VERSION " "
NS_ :

BS_:

BU_: ACU BDCM EPS BMS MCU VCU1 CDU TBOX EHB ESC Tester IHU PLG PTC EACP CLM ICU TAP ALM
BO_ 1077 MCU_Fr06_435: 8 MCU
 SG_ MCU6IGBTDrvChipAbnor : 53|1@0+ (1,0) [0|1] ""  TBOX
 SG_ MCU6VCUTimeout : 52|1@0+ (1,0) [0|1] ""  TBOX
 SG_ MCU6VCUDlcErr : 51|1@0+ (1,0) [0|1] ""  TBOX
 SG_ MCU6CanBusOff : 50|1@0+ (1,0) [0|1] ""  TBOX
 SG_ MCU6BMSTimeoutFault : 49|1@0+ (1,0) [0|1] ""  TBOX
 SG_ MCU6BMSTimeout : 48|1@0+ (1,0) [0|1] ""  TBOX
 SG_ MCU6BMSDlcErr : 47|1@0+ (1,0) [0|1] ""  TBOX
 SG_ MCU6SPIFPGA2CPLD : 46|1@0+ (1,0) [0|1] ""  TBOX
 SG_ MCU6DrvPwrAbnor : 45|1@0+ (1,0) [0|1] ""  TBOX
 SG_ MCU6Redundant12V : 44|1@0+ (1,0) [0|1] ""  TBOX
 SG_ MCU6HwFault_@2WG7274 : 43|1@0+ (1,0) [0|1] ""  TBOX
 SG_ MCU6HwWarn : 42|1@0+ (1,0) [0|1] ""  TBOX
 SG_ MCU6NTCRagChgErr : 41|1@0+ (1,0) [0|1] ""  TBOX
 SG_ MCU6ModReqErr : 40|1@0+ (1,0) [0|1] ""  TBOX
 SG_ MCU6WhlSpdDiffOv : 39|1@0+ (1,0) [0|1] ""  TBOX
 SG_ MCU6HvErr_@2WG7270 : 38|1@0+ (1,0) [0|1] ""  TBOX
 SG_ MCU6HvRddOv : 37|1@0+ (1,0) [0|1] ""  TBOX
 SG_ MCU6HvRddChkErr : 36|1@0+ (1,0) [0|1] ""  TBOX
 SG_ MCU6TempChkErr : 35|1@0+ (1,0) [0|1] ""  TBOX
 SG_ MCU6PosSensErr : 34|1@0+ (1,0) [0|1] ""  TBOX
 SG_ MCU6PhaCurUnrea : 33|1@0+ (1,0) [0|1] ""  TBOX
 SG_ MCU6FocCtrlErr_@2WG726F : 32|1@0+ (1,0) [0|1] ""  TBOX
 SG_ MCU6BatOffErr : 31|1@0+ (1,0) [0|1] ""  TBOX
 SG_ MCU6FwCurErr : 30|1@0+ (1,0) [0|1] ""  TBOX
 SG_ MCU6AscOrFwErr_@2WG726E : 29|1@0+ (1,0) [0|1] ""  TBOX
 SG_ MCU6flgDisChgFail : 28|1@0+ (1,0) [0|1] ""  TBOX
 SG_ MCU6TrqChkError_@2WG7268 : 27|1@0+ (1,0) [0|1] ""  TBOX
 SG_ MCU6EmacBlkd : 26|1@0+ (1,0) [0|1] ""  TBOX
 SG_ MCU6IphaErr : 25|1@0+ (1,0) [0|1] ""  TBOX
 SG_ MCU6OcLimErr : 24|1@0+ (1,0) [0|1] ""  TBOX
 SG_ MCU6InPwrFault_@2WG726D : 23|1@0+ (1,0) [0|1] ""  TBOX
 SG_ MCU6InPwrSevDer : 22|1@0+ (1,0) [0|1] ""  TBOX
 SG_ MCU6InPwrMilDer : 21|1@0+ (1,0) [0|1] ""  TBOX
 SG_ MCU6InPwrWarn : 20|1@0+ (1,0) [0|1] ""  TBOX
 SG_ MCU6SpdHiWA : 19|1@0+ (1,0) [0|1] ""  TBOX
 SG_ MCU6SpdOv : 18|1@0+ (1,0) [0|1] ""  TBOX
 SG_ MCU6PosSpeSigAmpRngErr : 17|1@0+ (1,0) [0|1] ""  TBOX
 SG_ MCU6PosSpeSigAmpRngDer : 16|1@0+ (1,0) [0|1] ""  TBOX
 SG_ MCU6PosSpeSigSinCosSqrErr_@2WG726C : 15|1@0+ (1,0) [0|1] ""  TBOX
 SG_ MCU6PhaCurOc_@2WG7273 : 14|1@0+ (1,0) [0|1] ""  TBOX
 SG_ MCU6PhaCurShr : 13|1@0+ (1,0) [0|1] ""  TBOX
 SG_ MCU6UKl30OvHiRng : 12|1@0+ (1,0) [0|1] ""  TBOX
 SG_ MCU6UKl30Ov : 11|1@0+ (1,0) [0|1] ""  TBOX
 SG_ MCU6UKl30OvLo : 10|1@0+ (1,0) [0|1] ""  TBOX
 SG_ MCU6UdcHiDerAct : 9|1@0+ (1,0) [0|1] ""  TBOX
 SG_ MCU6UdcLoDerAct : 8|1@0+ (1,0) [0|1] ""  TBOX
 SG_ MCU6UdcLnkOv_@2WG726A : 7|1@0+ (1,0) [0|1] ""  TBOX
 SG_ MCU6UdcLnkUnv_@2WG7269 : 6|1@0+ (1,0) [0|1] ""  TBOX
 SG_ MCU6TempEmDerAct : 5|1@0+ (1,0) [0|1] ""  TBOX
 SG_ MCU6TSttrShr : 4|1@0+ (1,0) [0|1] ""  TBOX
 SG_ MCU6TSttrOvHiLim_@2WG7272 : 3|1@0+ (1,0) [0|1] ""  TBOX
 SG_ MCU6TempIGBTDerAct : 2|1@0+ (1,0) [0|1] ""  TBOX
 SG_ MCU6TempIGBTShr : 1|1@0+ (1,0) [0|1] ""  TBOX
 SG_ MCU6TempIGBTHiLim_@2WG7271 : 0|1@0+ (1,0) [0|1] ""  TBOX
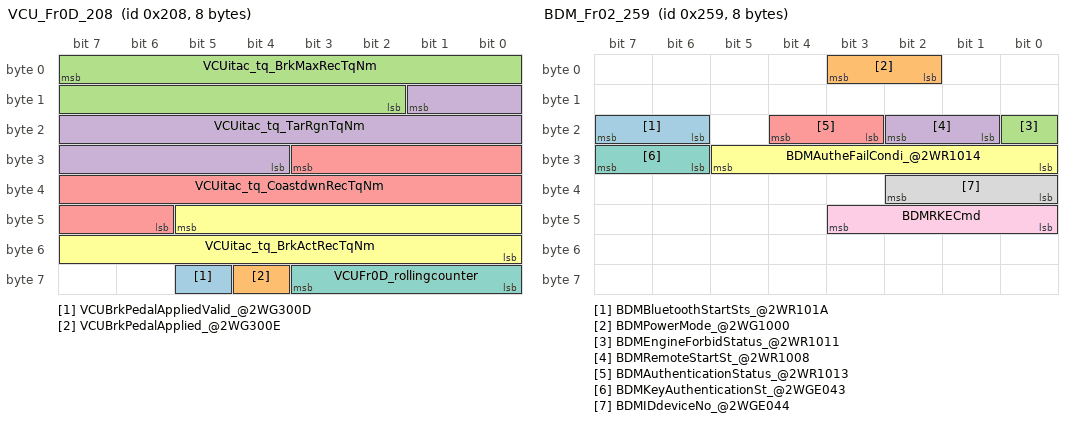
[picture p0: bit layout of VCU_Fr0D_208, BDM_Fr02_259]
BO_ 520 VCU_Fr0D_208: 8 VCU
 SG_ VCUBrkPedalAppliedValid_@2WG300D : 61|1@0+ (1,0) [0|0] ""  ESC
 SG_ VCUBrkPedalApplied_@2WG300E : 60|1@0+ (1,0) [0|0] ""  ESC
 SG_ VCUitac_tq_BrkMaxRecTqNm : 7|14@0+ (1,-16000) [-16000|0] "Nm"  ESC,EHB
 SG_ VCUitac_tq_TarRgnTqNm : 9|14@0+ (1,-16000) [-16000|0] "Nm"  ESC,EHB
 SG_ VCUitac_tq_CoastdwnRecTqNm : 27|14@0+ (1,-16000) [-16000|0] "Nm"  ESC,EHB
 SG_ VCUitac_tq_BrkActRecTqNm : 45|14@0+ (1,-16000) [-16000|0] "Nm"  ESC,EHB
 SG_ VCUFr0D_rollingcounter : 59|4@0+ (1,0) [0|15] ""  ESC,EHB
BO_ 698 APA_Fr02_2BA: 8 APA
 SG_ EXTAPAWorkStsCH_@2WG7063 : 39|3@0+ (1,0) [0|7] ""  VCU,EPS,ESC,ICU,IHU
BO_ 234 FLC_Fr01_0EA: 8 FLC
 SG_ EXTFLCStatus_@2WG7162 : 44|2@0+ (1,0) [0|3] ""  FLR
BO_ 522 FLR_Fr03_0x20A: 8 FLR
 SG_ EXTFLRAEBFailinfo_@2WG7161 : 31|2@0+ (1,0) [0|3] ""  ESC,ICU,IHU
BO_ 537 FLR_Fr02_0x219: 8 FLR
 SG_ EXTFLRACCSysFailure_@2WG7060 : 7|2@0+ (1,0) [0|3] ""  ESC,FLC,ICU
BO_ 1266 BTM_Fr01_4F2: 8 BTM
 SG_ BTM01ChargingCmd_@2WR1020 : 9|2@0+(1,0)[0|3] "" TBOX
BO_ 563 ACU_Fr01_233: 8 ACU
 SG_ ACUPsSeatBeltRSt_@2WGF045 : 7|2@0+(1,0)[0|3] "" Vector__XXX
 SG_ ACUDrvSeatBeltRSt_@2WGF044 : 5|2@0+(1,0)[0|3] "" Vector__XXX
 SG_ ACUAirBagFailSts_@2WG722D : 1|2@0+(1,0)[0|3] "" Vector__XXX
 SG_ ACUCrashOutputSts_@2WGE009 : 15|2@0+(1,0)[0|3] "" Vector__XXX
 SG_ EXTACUCrashOutputSts_@2WG7222 : 15|2@0+(1,0)[0|3] "" Vector__XXX
 SG_ ACU节点丢失_@2N001 : 15|2@0+(1,0)[0|3] "" Vector__XXX
BO_ 825 BDM_Fr01_339: 8 BDCM
 SG_ BDMAlarmMode_@2WG704C : 2|3@0+(1,0)[0|7] "" Vector__XXX
 SG_ BDMBackDoorAjar_@2WGC00E : 7|3@0+(1,0)[0|7] "" Vector__XXX
 SG_ BDMDriverDoorAjar_@2WGC00A : 9|2@0+(1,0)[0|3] "" Vector__XXX
 SG_ BDMPassDoorAjar_@2WGC00B : 11|2@0+(1,0)[0|3] "" Vector__XXX
 SG_ BDMRearDriverDoorAjar_@2WGC00C : 13|2@0+(1,0)[0|3] "" Vector__XXX
 SG_ BDMRearPassDoorAjar_@2WGC00D : 15|2@0+(1,0)[0|3] "" Vector__XXX
 SG_ BDMPositionLampSt_@2WGC003 : 16|1@0+(1,0)[0|1] "" Vector__XXX
 SG_ BDMBacklightStatus : 17|1@0+(1,0)[0|1] "" Vector__XXX
 SG_ BDMLowBeamSt_@2WGC009 : 18|1@0+(1,0)[0|1] "" Vector__XXX
 SG_ BDMLeftTurnLightSt : 19|1@0+(1,0)[0|1] "" Vector__XXX
 SG_ BDMRightTurnLightSt : 20|1@0+(1,0)[0|1] "" Vector__XXX
 SG_ BDMRearFogLampSt_@2WGC002 : 21|1@0+(1,0)[0|1] "" Vector__XXX
 SG_ BDMFrontFogLampSt : 22|1@0+(1,0)[0|1] "" Vector__XXX
 SG_ BDMDRLSt : 23|1@0+(1,0)[0|1] "" Vector__XXX
 SG_ BDMHighBeamSt_@2WGC008 : 24|1@0+(1,0)[0|1] "" Vector__XXX
 SG_ BDMHazardLampSt_@2WGF015 : 25|1@0+(1,0)[0|1] "" Vector__XXX
 SG_ BDMFrontWiperSt : 34|3@0+(1,0)[0|7] "" Vector__XXX
 SG_ BDMDoorLockSts_@2WGF000 : 38|1@0+(1,0)[0|1] "" Vector__XXX
 SG_ BDMRearDefrostSts : 39|1@0+(1,0)[0|1] "" Vector__XXX
 SG_ BDMLeftTurnLightSW_@2WGC006 : 31|2@0+ (1,0) [0|3] ""  TBOX
 SG_ BDMRightTurnLightSW_@2WGC007 : 31|2@0+ (1,0) [0|3] ""  TBOX
 SG_ BDMTrunkLockSts_@2WGF004 : 43|1@0+(1,0)[0|1] "" Vector__XXX
 SG_ BDMFindCarSts_@2WR1002 : 42|1@1+(1,0)[0|1] "" Vector__XXX
 SG_ BDCM节点丢失_@2N013 : 42|1@1+(1,0)[0|1] "" Vector__XXX
BO_ 601 BDM_Fr02_259: 8 BDCM
 SG_ BDMBluetoothStartSts_@2WR101A : 23|2@0+ (1,0) [0|0] ""  TBOX
 SG_ BDMPowerMode_@2WG1000 : 3|2@0+(1,0)[0|3] "" Vector__XXX
 SG_ BDMEngineForbidStatus_@2WR1011 : 16|1@0+(1,0)[0|1] "" Vector__XXX
 SG_ BDMRemoteStartSt_@2WR1008 : 18|2@0+(1,0)[0|3] "" Vector__XXX
 SG_ BDMAuthenticationStatus_@2WR1013 : 20|2@0+(1,0)[0|3] "" Vector__XXX
 SG_ BDMAutheFailCondi_@2WR1014 : 29|6@0+(1,0)[0|63] "" Vector__XXX
 SG_ BDMKeyAuthenticationSt_@2WGE043 : 31|2@0+(1,0)[0|3] "" Vector__XXX
 SG_ BDMIDdeviceNo_@2WGE044 : 34|3@0+(1,0)[0|7] "" Vector__XXX
 SG_ BDMRKECmd : 43|4@0+(1,0)[0|15] "" Vector__XXX
BO_ 618 BDM_Fr03_26A: 8 BDCM
 SG_ BDMDoorHandleSensorFailureInd : 1|1@0+(1,0)[0|1] "" Vector__XXX
 SG_ BDMBrakeLightSts_@2WGF01B : 2|1@0+(1,0)[0|1] "" Vector__XXX
 SG_ BDMKeyNotFindIndication : 10|1@0+(1,0)[0|1] "" Vector__XXX
 SG_ BDMKeyLowBatteryIndication : 11|1@0+(1,0)[0|1] "" Vector__XXX
 SG_ BDMKeyInIndication : 12|1@0+(1,0)[0|1] "" Vector__XXX
 SG_ BDMDepressBrakePedalIndication : 14|1@0+(1,0)[0|1] "" Vector__XXX
 SG_ BDMShiftGearToPNIndication : 15|1@0+(1,0)[0|1] "" Vector__XXX
 SG_ BDMShiftGearToPIndication : 16|1@0+(1,0)[0|1] "" Vector__XXX
 SG_ BDMBackupStartIndication : 17|1@0+(1,0)[0|1] "" Vector__XXX
 SG_ RearFogLampFailedSts : 42|1@0+(1,0)[0|1] "" Vector__XXX
 SG_ SSBFailedSts : 45|1@0+(1,0)[0|1] "" Vector__XXX
 SG_ CHMSLFailedSts : 21|1@0+(1,0)[0|1] "" Vector__XXX
 SG_ StopLampFailedSts_@2WG7149 : 22|1@0+(1,0)[0|1] "" Vector__XXX
 SG_ SRMSunroofPosition_@2WR1005 : 34|3@0+(1,0)[0|7] "" Vector__XXX
 SG_ SRMSunshadePosition : 47|2@0+(1,0)[0|3] "" Vector__XXX
 SG_ DriverHeatingStatus_@2WR100D : 50|3@0+(1,0)[0|7] "" Vector__XXX
 SG_ PassengerHeatingStatus_@2WR100E : 53|3@0+(1,0)[0|7] "" Vector__XXX
 SG_ SHMLHFailure : 57|1@0+(1,0)[0|1] "" Vector__XXX
 SG_ SHMRHFailure : 56|1@0+(1,0)[0|1] "" Vector__XXX
BO_ 906 BDM_Fr04_38A: 8 BDCM
 SG_ BDMRtyreStatus : 0|1@0+(1,0)[0|1] "" Vector__XXX
 SG_ BDMRLTyreLearntSt : 1|1@0+(1,0)[0|1] "" Vector__XXX
 SG_ BDMRLTyrePressureWarn_@2WG500F : 3|2@0+(1,0)[0|3] "" Vector__XXX
 SG_ BDMRLTyreTemperatureWarn_@2WG5011 : 4|1@0+(1,0)[0|1] "" Vector__XXX
 SG_ BDMRLTyreQucikLeak_@2WG500E : 5|1@0+(1,0)[0|1] "" Vector__XXX
 SG_ BDMRLTyreSensorFailure_@2WG500D : 6|1@0+(1,0)[0|1] "" Vector__XXX
 SG_ BDMRLTyreLowBattery_@2WG5012 : 7|1@0+(1,0)[0|1] "" Vector__XXX
 SG_ BDMRLTyrePressure_@2WGF024 : 15|8@0+(3.137,0)[0|797] "" Vector__XXX
 SG_ BDMRLTyreTemperature_@2WGF023 : 23|8@0+(1,-50)[-50|204] "" Vector__XXX
 SG_ BDMRRTyreLearntSt : 25|1@0+(1,0)[0|1] "" Vector__XXX
 SG_ BDMRRTyrePressureWarn_@2WG5015 : 27|2@0+(1,0)[0|3] "" Vector__XXX
 SG_ BDMRRTyreTemperatureWarn_@2WG5017 : 28|1@0+(1,0)[0|1] "" Vector__XXX
 SG_ BDMRRTyreQucikLeak_@2WG5014 : 29|1@0+(1,0)[0|1] "" Vector__XXX
 SG_ BDMRRTyreSensorFailure_@2WG5013 : 30|1@0+(1,0)[0|1] "" Vector__XXX
 SG_ BDMRRTyreLowBattery_@2WG5018 : 31|1@0+(1,0)[0|1] "" Vector__XXX
 SG_ BDMRRTyrePressure_@2WGF022 : 39|8@0+(3.137,0)[0|797] "" Vector__XXX
 SG_ BDMRRTyreTemperature_@2WGF021 : 47|8@0+(1,-50)[-50|204] "" Vector__XXX
BO_ 874 BDM_Fr05_36A: 8 BDCM
 SG_ BDMFtyreStatus : 0|1@0+(1,0)[0|1] "" Vector__XXX
 SG_ BDMFLTyreLearntSt : 1|1@0+(1,0)[0|1] "" Vector__XXX
 SG_ BDMFLTyrePressureWarn_@2WG5003 : 3|2@0+(1,0)[0|3] "" Vector__XXX
 SG_ BDMFLTyreTemperatureWarn_@2WG5005 : 4|1@0+(1,0)[0|1] "" Vector__XXX
 SG_ BDMFLTyreQucikLeak_@2WG5002 : 5|1@0+(1,0)[0|1] "" Vector__XXX
 SG_ BDMFLTyreSensorFailure_@2WG5001 : 6|1@0+(1,0)[0|1] "" Vector__XXX
 SG_ BDMFLTyreLowBattery_@2WG5006 : 7|1@0+(1,0)[0|1] "" Vector__XXX
 SG_ BDMFLTyrePressure_@2WGF020 : 15|8@0+(3.137,0)[0|797] "" Vector__XXX
 SG_ BDMFLTyreTemperature_@2WGF01F : 23|8@0+(1,-50)[-50|204] "" Vector__XXX
 SG_ BDMFRTyreLearntSt : 25|1@0+(1,0)[0|1] "" Vector__XXX
 SG_ BDMFRTyrePressureWarn_@2WG5009 : 27|2@0+(1,0)[0|3] "" Vector__XXX
 SG_ BDMFRTyreTemperatureWarn_@2WG500B : 28|1@0+(1,0)[0|1] "" Vector__XXX
 SG_ BDMFRTyreQucikLeak_@2WG5008 : 29|1@0+(1,0)[0|1] "" Vector__XXX
 SG_ BDMFRTyreSensorFailure_@2WG5007 : 30|1@0+(1,0)[0|1] "" Vector__XXX
 SG_ BDMFRTyreLowBattery_@2WG500C : 31|1@0+(1,0)[0|1] "" Vector__XXX
 SG_ BDMFRTyrePressure_@2WGF01E : 39|8@0+(3.137,0)[0|797] "" Vector__XXX
 SG_ BDMFRTyreTemperature_@2WGF01D : 47|8@0+(1,-50)[-50|204] "" Vector__XXX
 SG_ BDMSystemFailure_@2WG704B : 55|2@0+(1,0)[0|3] "" Vector__XXX
BO_ 225 EPS_Fr02_0E1: 8 EPS
 SG_ EPSFailSts_@2WG724E : 21|1@0+(1,0)[0|1] "" Vector__XXX
 SG_ EPSFr02MsgCounter : 55|4@0+(1,0)[0|15] "" Vector__XXX
 SG_ EPSFr02Checksum : 63|8@0+(1,0)[0|255] "" Vector__XXX
 SG_ EPSDriveSteerTorqueValid : 15|1@0+(1,0)[0|1] "" Vector__XXX
 SG_ EPS节点丢失_@2N006 : 15|1@0+(1,0)[0|1] "" Vector__XXX
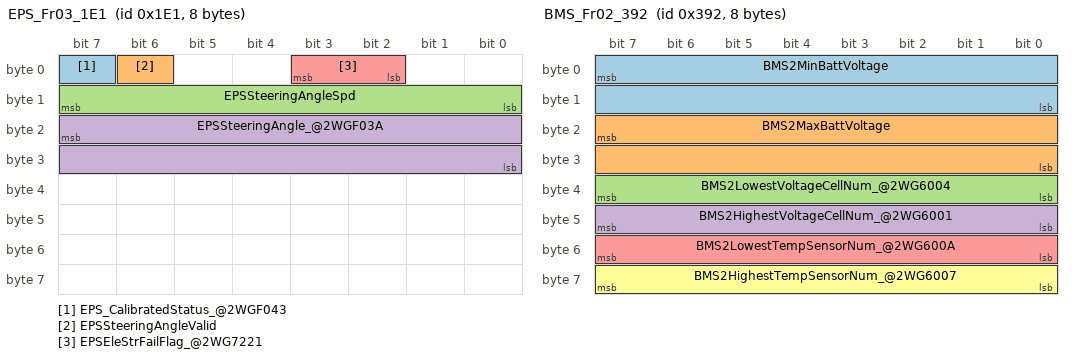
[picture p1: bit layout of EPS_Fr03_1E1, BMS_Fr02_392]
BO_ 481 EPS_Fr03_1E1: 8 EPS
 SG_ EPS_CalibratedStatus_@2WGF043 : 7|1@0+ (1,0) [0|1] "" Vector__XXX
 SG_ EPSSteeringAngleValid : 6|1@0+(1,0)[0|1] "" Vector__XXX
 SG_ EPSSteeringAngleSpd : 15|8@0+(4,0)[0|1020] "dgree/s" Vector__XXX
 SG_ EPSSteeringAngle_@2WGF03A : 23|16@0+(0.1,-720)[-720|720] "dgree" Vector__XXX
 SG_ EPSEleStrFailFlag_@2WG7221 : 3|2@0+(1,0)[0|3] "" Vector__XXX
BO_ 872 BMS_Fr01_368: 8 BMS
 SG_ BMS1MaxDischargeCurrent : 7|16@0+(0.05,-1600)[0|1024] "A" Vector__XXX
 SG_ BMS1MaxChargeCurrent : 23|16@0+(0.05,-1600)[0|1024] "A" Vector__XXX
 SG_ BMS1StateOfCharge_@2WG1007 : 39|16@0+(0.01,0)[0|100] "%" Vector__XXX
 SG_ BMS1PowerBattMaintainLightReq : 52|1@0+(1,0)[0|1] "" Vector__XXX
 SG_ BMS1PowerBattDiscntWarnLightSts : 53|1@0+(1,0)[0|1] "" Vector__XXX
 SG_ BMS1itacstsChrgGunCnctLi_@2WGE028 : 55|2@0+(1,0)[0|3] "" Vector__XXX
 SG_ BMS1ChrgGunCnctLi_@2WR101B : 55|2@0+(1,0)[0|3] "" Vector__XXX
 SG_ BMS1BattPackType : 50|6@0+(1,0)[0|63] "" Vector__XXX
BO_ 914 BMS_Fr02_392: 8 BMS
 SG_ BMS2MinBattVoltage : 7|16@0+(0.05,0)[0|1000] "V" Vector__XXX
 SG_ BMS2MaxBattVoltage : 23|16@0+(0.05,0)[0|1000] "V" Vector__XXX
 SG_ BMS2LowestVoltageCellNum_@2WG6004 : 39|8@0+(1,0)[0|200] "" Vector__XXX
 SG_ BMS2HighestVoltageCellNum_@2WG6001 : 47|8@0+(1,0)[0|200] "" Vector__XXX
 SG_ BMS2LowestTempSensorNum_@2WG600A : 55|8@0+(1,0)[0|200] "" Vector__XXX
 SG_ BMS2HighestTempSensorNum_@2WG6007 : 63|8@0+(1,0)[0|200] "" Vector__XXX
BO_ 858 BMS_Fr03_35A: 8 BMS
 SG_ BMS3BatteryCurrent_@2WG1006 : 7|16@0+(0.05,-1600)[-600|600] "A" Vector__XXX
 SG_ BMS3BatterypackCurrent_@2WG83FF : 7|16@0+(0.05,-1600)[-600|600] "A" Vector__XXX
 SG_ BMS3BatteryVoltage_@2WG1005 : 23|16@0+(0.05,0)[0|1000] "V" Vector__XXX
 SG_ BMS3BatterypackVoltage_@2WG83FE : 23|16@0+(0.05,0)[0|1000] "V" Vector__XXX
 SG_ BMS3AverageBattTemp : 55|8@0+(1,-40)[-40|125] "℃" Vector__XXX
 SG_ BMS3StateOfHealth : 63|8@0+(1,0)[0|100] "%" Vector__XXX
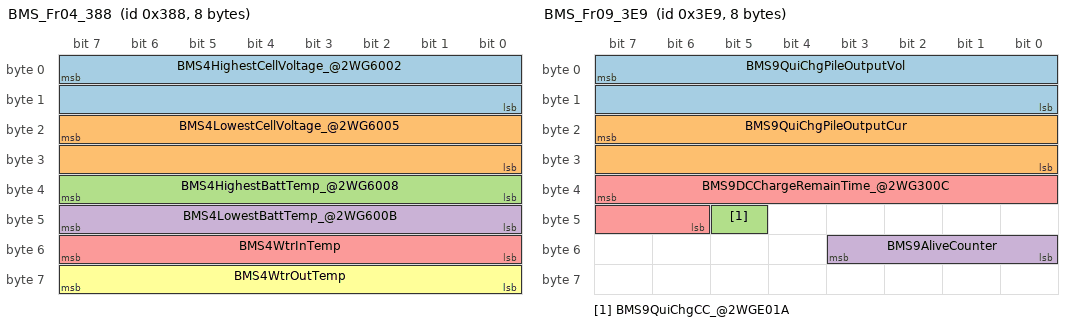
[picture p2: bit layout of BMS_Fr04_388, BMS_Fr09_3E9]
BO_ 904 BMS_Fr04_388: 8 BMS
 SG_ BMS4HighestCellVoltage_@2WG6002 : 7|16@0+(1,0)[0|5000] "mv" Vector__XXX
 SG_ BMS4LowestCellVoltage_@2WG6005 : 23|16@0+(1,0)[0|5000] "mv" Vector__XXX
 SG_ BMS4HighestBattTemp_@2WG6008 : 39|8@0+(1,-40)[-40|125] "℃" Vector__XXX
 SG_ BMS4LowestBattTemp_@2WG600B : 47|8@0+(1,-40)[-40|125] "℃" Vector__XXX
 SG_ BMS4WtrInTemp : 55|8@0+(1,-40)[-40|125] "℃" Vector__XXX
 SG_ BMS4WtrOutTemp : 63|8@0+(1,-40)[-40|125] "℃" Vector__XXX
BO_ 646 BMS_Fr06_286: 8 BMS
 SG_ BMS6Sts_@2WGE00F : 1|2@0+(1,0)[0|3] "" Vector__XXX
 SG_ BMS6PosBattContSts_@2WGE00E : 9|2@0+(1,0)[0|3] "" Vector__XXX
 SG_ BMS6NegBattContSts_@2WGE00F : 11|2@0+(1,0)[0|3] "" Vector__XXX
 SG_ BMS6dischgActiveFltCategory_@2WR1028 : 35|4@0+(1,0)[0|15] "" Vector__XXX
 SG_ EXTBMS6dischgActiveFltCategory_@2WG725D : 35|4@0+(1,0)[0|15] "" Vector__XXX
 SG_ BMS6chgActiveFltCategory : 39|4@0+(1,0)[0|15] "" Vector__XXX
 SG_ BMS6DCChargeContSts_@2WGE011 : 47|2@0+(1,0)[0|3] "" Vector__XXX
 SG_ BMS6InterlockSts_@2WG7210 : 55|2@0+(1,0)[0|3] "" Vector__XXX
 SG_ BMS6ElectronicLockFlt : 49|2@0+(1,0)[0|3] "" Vector__XXX
 SG_ BMS6presentActivityFault : 63|8@0+(1,0)[0|128] "" Vector__XXX
 SG_ BMS6ChargeFlt : 52|2@0+(1,0)[0|3] "" Vector__XXX
 SG_ BMS6S2Sts_@2WGE02F : 50|1@0+(1,0)[0|1] "" Vector__XXX
 SG_ BMS6BatCircWtrPumWrkSts_@2WGE008 : 23|16@0+(0.1,0)[0|100] "%" Vector__XXX
 SG_ BMS6PrechargeContSts_@2WGE010 : 15|2@0+(1,0)[0|3] "" Vector__XXX
 SG_ BMS节点丢失_@2N002 : 15|2@0+(1,0)[0|3] "" Vector__XXX
BO_ 631 BMS_Fr07_277: 8 BMS
 SG_ BMS7TempRiseFastFlt_@2WG5000 : 27|2@0+(1,0)[0|3] "" Vector__XXX
 SG_ BMS7CellOverTempSts_@2WG7201 : 1|2@0+(1,0)[0|3] "" Vector__XXX
 SG_ BMS7CellUnderTempSts : 3|2@0+(1,0)[0|3] "" Vector__XXX
 SG_ BMS7CellOverVoltageSts_@2WG7205 : 5|2@0+(1,0)[0|3] "" Vector__XXX
 SG_ BMS7CellUnderVoltageSts_@2WG7206 : 7|2@0+(1,0)[0|3] "" Vector__XXX
 SG_ BMS7OverVoltageSts_@2WG7202 : 9|2@0+(1,0)[0|3] "" Vector__XXX
 SG_ BMS7UnderVoltageSts_@2WG7203 : 11|2@0+(1,0)[0|3] "" Vector__XXX
 SG_ BMS7UnderSOCSts_@2WG7204 : 13|2@0+(1,0)[0|3] "" Vector__XXX
 SG_ BMS7OverCurrentSts_@2WR1023 : 15|2@0+(1,0)[0|3] "" Vector__XXX
 SG_ EXTBMS7OverCurrentSts_@2WG725E : 15|2@0+(1,0)[0|3] "" Vector__XXX
 SG_ BMS7IsolSuperSts_@2WG720B : 17|2@0+(1,0)[0|3] "" Vector__XXX
 SG_ BMS7TempDiffSts_@2WG7200 : 19|2@0+(1,0)[0|3] "" Vector__XXX
 SG_ BMS7DiagSts_@2WR1024 : 21|2@0+(1,0)[0|3] "" Vector__XXX
 SG_ EXTBMS7DiagSts_@2WG7064 : 21|2@0+(1,0)[0|3] "" Vector__XXX
 SG_ BMS7CellConsistencySts_@2WG720A : 23|2@0+(1,0)[0|3] "" Vector__XXX
 SG_ BMS7BatteryState : 25|2@0+(1,0)[0|3] "" Vector__XXX
BO_ 1288 BMS_Fr08_508: 8 BMS
 SG_ BMS8ChargeCCSig_@2WGE018 : 0|1@0+(1,0)[0|1] "" Vector__XXX
 SG_ BMS8ChargeCPSig_@2WGE019 : 1|1@0+(1,0)[0|1] "" Vector__XXX
 SG_ BMS8ChargeState_@2WGF029 : 4|3@0+(1,0)[0|7] "" Vector__XXX
 SG_ GBBMS8ChargeState_@2WG1001 : 4|3@0+(1,0)[0|7] "" Vector__XXX
 SG_ CMPTBMS8ChargeState_@2WGE01F : 4|3@0+(1,0)[0|7] "" Vector__XXX
 SG_ BMS8SlowChgMaxACCurrent : 23|16@0+(0.05,-1600)[0|600] "A" Vector__XXX
 SG_ BMS8SumOfCellNum_@2WG8000 : 39|8@0+(1,0)[0|254] "" Vector__XXX
 SG_ BMS8SumOfTSnsrNum_@2WG9000 : 47|8@0+(1,0)[0|254] "" Vector__XXX
 SG_ BMS8AliveCounter : 55|4@0+(1,0)[0|15] "" Vector__XXX
 SG_ BMS8ChargeSts_@2WR100F : 5|1@0+(1,0)[0|1] "" Vector__XXX
 SG_ BMS8ChargeAppointmentEn_@2WR1015 : 6|1@0+(1,0)[0|1] "" Vector__XXX
 SG_ BMS8ChargeAppointmentTimeFb : 15|8@0+(10,0)[0|1440] "min" Vector__XXX
 SG_ BMS8ACChargeRemainTime_@2WGF025 : 51|10@0+(1,0)[0|1023] "min" Vector__XXX
BO_ 1001 BMS_Fr09_3E9: 8 BMS
 SG_ BMS9QuiChgPileOutputVol : 7|16@0+(0.05,0)[0|1000] "V" Vector__XXX
 SG_ BMS9QuiChgPileOutputCur : 23|16@0+(0.05,-1600)[0|600] "A" Vector__XXX
 SG_ BMS9QuiChgCC_@2WGE01A : 45|1@0+(1,0)[0|1] "" Vector__XXX
 SG_ BMS9AliveCounter : 51|4@0+(1,0)[0|15] "" Vector__XXX
 SG_ BMS9DCChargeRemainTime_@2WG300C : 39|10@0+(1,0)[0|1023] "min" Vector__XXX
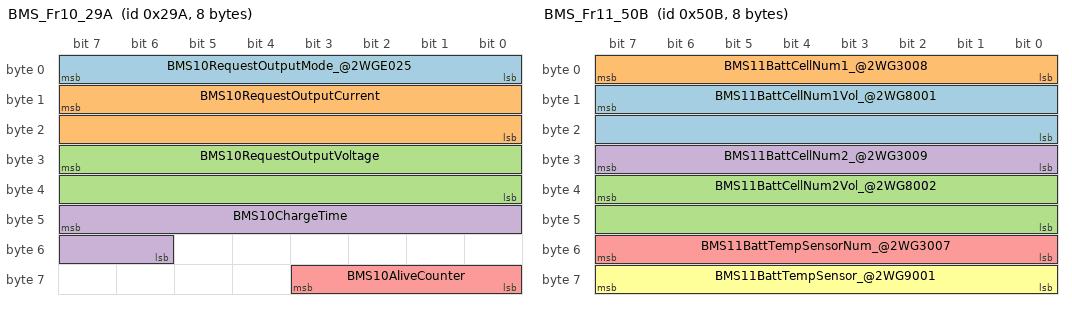
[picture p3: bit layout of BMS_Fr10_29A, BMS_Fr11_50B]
BO_ 666 BMS_Fr10_29A: 8 BMS
 SG_ BMS10RequestOutputMode_@2WGE025 : 7|8@0+(1,0)[0|255] "" Vector__XXX
 SG_ BMS10RequestOutputCurrent : 15|16@0+(0.05,0)[0|400] "A" Vector__XXX
 SG_ BMS10RequestOutputVoltage : 31|16@0+(0.05,0)[0|1000] "V" Vector__XXX
 SG_ BMS10ChargeTime : 47|10@0+(1,0)[0|1023] "" Vector__XXX
 SG_ BMS10AliveCounter : 59|4@0+(1,0)[0|15] "" Vector__XXX
BO_ 1291 BMS_Fr11_50B: 8 BMS
 SG_ BMS11BattCellNum1Vol_@2WG8001 : 15|16@0+ (1,0) [0|5000] ""  Vector__XXX
 SG_ BMS11BattCellNum1_@2WG3008 : 7|8@0+ (1,0) [0|255] ""  Vector__XXX
 SG_ BMS11BattCellNum2Vol_@2WG8002 : 39|16@0+ (1,0) [0|5000] ""  Vector__XXX
 SG_ BMS11BattCellNum2_@2WG3009 : 31|8@0+ (1,0) [0|255] ""  Vector__XXX
 SG_ BMS11BattTempSensorNum_@2WG3007 : 55|8@0+ (1,0) [0|255] ""  Vector__XXX
 SG_ BMS11BattTempSensor_@2WG9001 : 63|8@0+ (1,-40) [-40|125] ""  Vector__XXX
BO_ 170 MCU_Fr01_0AA: 8 MCU
 SG_ MCU1presentActivityFault : 63|8@0+(1,0)[0|128] "" Vector__XXX
 SG_ MCU1MaxAvailableTorque_@2WGE00D : 7|16@0+(0.05,0)[0|1024] "Nm" Vector__XXX
 SG_ MCU1MotorSpeed_@2WG2002 : 23|16@0+(0.5,-16000)[-16000|16000] "Rpm" Vector__XXX
 SG_ MCU1AliveCounter : 51|4@0+(1,0)[0|15] "" Vector__XXX
 SG_ MCU1ControllerTorque_@2WGE00B : 39|16@0+(0.05,-1024)[-1024|1024] "Nm" Vector__XXX
 SG_ MCU1MotorControllerTorque_@2WG2003 : 39|16@0+(0.05,-1024)[-1024|1024] "Nm" Vector__XXX
 SG_ MCU节点丢失_@2N004 : 39|16@0+(0.05,-1024)[-1024|1024] "Nm" Vector__XXX
BO_ 187 MCU_Fr02_0BB: 8 MCU
 SG_ MCU2FaultLevel_@2WR1022 : 2|2@0+(1,0)[0|3] "" Vector__XXX
 SG_ EXTMCU2FaultLevel_@2WG7066 : 2|2@0+(1,0)[0|3] "" Vector__XXX
 SG_ MCU2MotorBlockWarning : 4|1@0+(1,0)[0|1] "" Vector__XXX
 SG_ MCU22OpenProtionLockFault_@2WG7238 : 5|1@0+(1,0)[0|1] "" Vector__XXX
 SG_ MCU2CoolingSystemFault : 6|1@0+(1,0)[0|1] "" Vector__XXX
 SG_ MCU2SelfcheckFault : 7|1@0+(1,0)[0|1] "" Vector__XXX
 SG_ MCU2SensorCheckFault : 12|1@0+(1,0)[0|1] "" Vector__XXX
 SG_ MCU2BatteryCheckFault_@2WG7225 : 13|1@0+(1,0)[0|1] "" Vector__XXX
 SG_ MCU2MotorLackofPhaseFault : 14|1@0+(1,0)[0|1] "" Vector__XXX
 SG_ MCU2RDCAlignmentFault : 15|1@0+(1,0)[0|1] "" Vector__XXX
 SG_ MCU2PhaseOvercurrentFault : 32|1@0+(1,0)[0|1] "" Vector__XXX
 SG_ MCU2InverterFault_@2WG7237 : 33|1@0+(1,0)[0|1] "" Vector__XXX
 SG_ MCU2SensorSupplyVoltageFault : 39|1@0+(1,0)[0|1] "" Vector__XXX
 SG_ MCU2DClinkOvercurrentFault : 40|1@0+(1,0)[0|1] "" Vector__XXX
 SG_ MCU2GateDriDesaturFault_@2WG7227 : 41|1@0+(1,0)[0|1] "" Vector__XXX
 SG_ MCU2MotorPosSensorFault_@2WG7228 : 42|1@0+(1,0)[0|1] "" Vector__XXX
 SG_ MCU22DischargeOverTime : 43|1@0+(1,0)[0|1] "" Vector__XXX
 SG_ MCU22SumPhaseCurrentOverThd : 44|1@0+(1,0)[0|1] "" Vector__XXX
 SG_ MCU2MotorOvertempFault_@2WG7211 : 46|2@0+(1,0)[0|3] "" Vector__XXX
 SG_ MCU22AphaseOvercurrentWarning : 47|1@0+(1,0)[0|1] "" Vector__XXX
 SG_ MCU22BphaseOvercurrentWarning : 48|1@0+(1,0)[0|1] "" Vector__XXX
 SG_ MCU2CphaseOvercurrentWarning : 49|1@0+(1,0)[0|1] "" Vector__XXX
 SG_ MCU2InverterOvertempFault_@2WG720F : 51|2@0+(1,0)[0|3] "" Vector__XXX
 SG_ MCU2RxCANFailed_@2WG7144 : 52|1@0+(1,0)[0|1] "" Vector__XXX
 SG_ MCU2LVPowerSupplyFault : 53|1@0+(1,0)[0|1] "" Vector__XXX
 SG_ MCU2HVBatteryConnectstates : 55|1@0+(1,0)[0|1] "" Vector__XXX
 SG_ MCU2VCUInverterstates : 56|1@0+(1,0)[0|1] "" Vector__XXX
 SG_ MCU2SafetyFault : 57|1@0+(1,0)[0|1] "" Vector__XXX
 SG_ MCU2ModeError : 58|1@0+(1,0)[0|1] "" Vector__XXX
 SG_ MCU2GateDriverVoltageSupplyFault : 59|1@0+(1,0)[0|1] "" Vector__XXX
 SG_ MCU2Fr02AliveCounter : 63|4@0+(1,0)[0|15] "" Vector__XXX
BO_ 972 MCU_Fr03_3CC: 8 MCU
 SG_ MCU3DClinkVoltage_@2WG2005 : 7|16@0+(0.05,0)[0|600] "V" Vector__XXX
 SG_ MCU3DClinkCurrent_@2WG2006 : 23|16@0+(0.05,-512)[-512|512] "A" Vector__XXX
 SG_ MCU3Mode_@2WGE00A : 39|3@0+(1,0)[0|7] "" Vector__XXX
 SG_ GBMCU3Mode_@2WG2000 : 39|3@0+(1,0)[0|7] "" Vector__XXX
 SG_ MCU3InverterTemperature_@2WG2001 : 55|8@0+(1,-48)[-48|206] "℃" Vector__XXX
 SG_ MCU3MotorTemperature_@2WG2004 : 63|8@0+(1,-48)[-48|206] "℃" Vector__XXX
 SG_ MCU3HVILDCBus_@2WG3001 : 36|1@0+(1,0)[0|1] "" Vector__XXX
BO_ 1072 MCU_Fr04_430: 8 MCU
 SG_ MCU4AlOfsNoPlaus : 0|1@0+(1,0)[0|1] "" Vector__XXX
 SG_ MCU4CanBusOff : 1|1@0+(1,0)[0|1] "" Vector__XXX
 SG_ MCU4EppPosMonShrGnd : 2|1@0+(1,0)[0|1] "" Vector__XXX
 SG_ MCU4EppPosShrGnd : 3|1@0+(1,0)[0|1] "" Vector__XXX
 SG_ MCU4IUMonOvHiRng : 4|1@0+(1,0)[0|1] "" Vector__XXX
 SG_ MCU4IUMonOvLoRng : 5|1@0+(1,0)[0|1] "" Vector__XXX
 SG_ MCU4IUOc : 6|1@0+(1,0)[0|1] "" Vector__XXX
 SG_ MCU4IUOvHiRng : 7|1@0+(1,0)[0|1] "" Vector__XXX
 SG_ MCU4IUOvLoRng : 8|1@0+(1,0)[0|1] "" Vector__XXX
 SG_ MCU4IVMonOvHiRng : 9|1@0+(1,0)[0|1] "" Vector__XXX
 SG_ MCU4IVMonOvLoRng : 10|1@0+(1,0)[0|1] "" Vector__XXX
 SG_ MCU4IVOc_@2WG7223 : 11|1@0+(1,0)[0|1] "" Vector__XXX
 SG_ MCU4IVOvHiRng : 12|1@0+(1,0)[0|1] "" Vector__XXX
 SG_ MCU4IVOvLoRng : 13|1@0+(1,0)[0|1] "" Vector__XXX
 SG_ MCU4IWMonOvHiRng : 14|1@0+(1,0)[0|1] "" Vector__XXX
 SG_ MCU4IWMonOvLoRng : 15|1@0+(1,0)[0|1] "" Vector__XXX
 SG_ MCU4IWOc_@2WG7224 : 16|1@0+(1,0)[0|1] "" Vector__XXX
 SG_ MCU4IWOvHiRng : 17|1@0+(1,0)[0|1] "" Vector__XXX
 SG_ MCU4IWOvLoRng : 18|1@0+(1,0)[0|1] "" Vector__XXX
 SG_ MCU4IphaOC_@2WG7229 : 19|1@0+(1,0)[0|1] "" Vector__XXX
 SG_ MCU4IphaOffCal : 20|1@0+(1,0)[0|1] "" Vector__XXX
 SG_ MCU4MosTHiRng : 21|1@0+(1,0)[0|1] "" Vector__XXX
 SG_ MCU4NFltHA : 22|1@0+(1,0)[0|1] "" Vector__XXX
 SG_ MCU4NFltHB : 23|1@0+(1,0)[0|1] "" Vector__XXX
 SG_ MCU4NFltLA : 24|1@0+(1,0)[0|1] "" Vector__XXX
 SG_ MCU4NFltLB : 25|1@0+(1,0)[0|1] "" Vector__XXX
 SG_ MCU4RslvDos : 26|1@0+(1,0)[0|1] "" Vector__XXX
 SG_ MCU4RslvLos : 27|1@0+(1,0)[0|1] "" Vector__XXX
 SG_ MCU4RslvLot : 28|1@0+(1,0)[0|1] "" Vector__XXX
 SG_ MCU4StallmotRng : 29|1@0+(1,0)[0|1] "" Vector__XXX
 SG_ MCU4HwPhaCurPosBackErr : 30|1@0+(1,0)[0|1] "" Vector__XXX
 SG_ MCU4HwPhaCurNegBackErr : 31|1@0+(1,0)[0|1] "" Vector__XXX
 SG_ MCU4TimeovRng : 32|1@0+(1,0)[0|1] "" Vector__XXX
 SG_ MCU4TSttr1OvHiLim : 33|1@0+(1,0)[0|1] "" Vector__XXX
 SG_ MCU4TSttr1OvLoLim : 34|1@0+(1,0)[0|1] "" Vector__XXX
 SG_ MCU4TSttr2OvHiLim : 35|1@0+(1,0)[0|1] "" Vector__XXX
 SG_ MCU4TSttr2OvLoLim : 36|1@0+(1,0)[0|1] "" Vector__XXX
 SG_ MCU4TUErrOff : 37|1@0+(1,0)[0|1] "" Vector__XXX
 SG_ MCU4TVErrOff : 38|1@0+(1,0)[0|1] "" Vector__XXX
 SG_ MCU4TWErrOff : 39|1@0+(1,0)[0|1] "" Vector__XXX
 SG_ MCU4tDBCTempUHiLom : 40|1@0+(1,0)[0|1] "" Vector__XXX
 SG_ MCU4tDBCTempULoLom : 41|1@0+(1,0)[0|1] "" Vector__XXX
 SG_ MCU4tDBCTempVHiLom : 42|1@0+(1,0)[0|1] "" Vector__XXX
 SG_ MCU4tDBCTempVLoLom : 43|1@0+(1,0)[0|1] "" Vector__XXX
 SG_ MCU4tDBCTempWHiLom : 44|1@0+(1,0)[0|1] "" Vector__XXX
 SG_ MCU4tDBCTempWLoLom : 45|1@0+(1,0)[0|1] "" Vector__XXX
 SG_ MCU4QtShrGnd : 46|1@0+(1,0)[0|1] "" Vector__XXX
 SG_ MCU4SttrTemp1ShrGnd : 47|1@0+(1,0)[0|1] "" Vector__XXX
 SG_ MCU4SttrTemp2ShrGnd : 48|1@0+(1,0)[0|1] "" Vector__XXX
 SG_ MCU4UMonShrGnd : 49|1@0+(1,0)[0|1] "" Vector__XXX
 SG_ MCU4VMonShrGnd : 50|1@0+(1,0)[0|1] "" Vector__XXX
 SG_ MCU4WMonShrGnd : 51|1@0+(1,0)[0|1] "" Vector__XXX
 SG_ MCU4UShrGnd : 52|1@0+(1,0)[0|1] "" Vector__XXX
 SG_ MCU4VShrGnd : 53|1@0+(1,0)[0|1] "" Vector__XXX
 SG_ MCU4WShrGnd : 54|1@0+(1,0)[0|1] "" Vector__XXX
 SG_ MCU4UKl30Ov : 55|1@0+(1,0)[0|1] "" Vector__XXX
 SG_ MCU4UKl30Unv_@2WG7239 : 56|1@0+(1,0)[0|1] "" Vector__XXX
 SG_ MCU4VcuRecOvTime : 57|1@0+(1,0)[0|1] "" Vector__XXX
 SG_ MCU4UdcLnkOvHiRng_@2WG702A : 59|2@0+(1,0)[0|3] "" Vector__XXX
 SG_ MCU4UdcLnkOvLoRng_@2WG702B : 61|2@0+(1,0)[0|3] "" Vector__XXX
 SG_ MCU4OverSpdDetn : 63|2@0+(1,0)[0|3] "" Vector__XXX
BO_ 200 VCU_Fr01_0C8: 8 VCU1
 SG_ VCU1TorqueCommand_@2WGE000 : 7|16@0+(0.05,-1024)[-1024|1024] "Nm" Vector__XXX
 SG_ VCU1SpeedCommand_@2WGE001 : 23|16@0+(0.5,-16000)[-16000|16000] "RPM" Vector__XXX
 SG_ VCU1ModeCommand : 36|3@0+(1,0)[0|7] "" Vector__XXX
 SG_ VCU1MCUEnable : 33|1@0+(1,0)[0|1] "" Vector__XXX
 SG_ VCU1HvEmgystatus : 43|1@0+(1,0)[0|1] "" Vector__XXX
 SG_ VCU1PMMSysSt_@2WGE002 : 42|3@0+(1,0)[0|7] "" Vector__XXX
 SG_ VCU1PMMPwrUpSt_@2WGE003 : 55|3@0+(1,0)[0|7] "" Vector__XXX
 SG_ VCU1PMMPwrDwnSt_@2WGE004 : 52|3@0+(1,0)[0|7] "" Vector__XXX
 SG_ VCU1PMMTmOuSt : 39|3@0+(1,0)[0|7] "" Vector__XXX
 SG_ VCU1AliveCounter : 47|4@0+(1,0)[0|15] "" Vector__XXX
 SG_ VCU1Checksum : 63|8@0+(1,0)[0|255] "" Vector__XXX
 SG_ VCU1节点丢失_@2N005 : 63|8@0+(1,0)[0|255] "" Vector__XXX
BO_ 850 VCU_Fr02_352: 8 VCU1
 SG_ VCU2IntegHVIL : 4|1@0+ (1,0) [0|0] ""  Vector__XXX
 SG_ VCU2presentActivityFault : 55|8@0+(1,0)[0|128] "" Vector__XXX
 SG_ VCU2ControlHVDischarge : 1|2@0+(1,0)[0|3] "" Vector__XXX
 SG_ VCU2HVILAttach : 5|1@0+(1,0)[0|1] "" Vector__XXX
 SG_ VCU2PwrTrainFailureLevel_@2WR102A : 7|2@0+(1,0)[0|3] "" Vector__XXX
 SG_ EXTVCU2PwrTrainFailureLevel_@2WG7067 : 7|2@0+(1,0)[0|3] "" Vector__XXX
 SG_ VCU2HVLoadRTPwr : 15|16@0+(1,0)[0|65534] "w" Vector__XXX
 SG_ VCU2DCDCPowerLimit : 31|8@0+(0.01,0)[0|2.54] "Kw" Vector__XXX
 SG_ VCU2DCDCOutputVolCom : 39|10@0+(0.05,0)[0|51.15] "V" Vector__XXX
 SG_ VCU2AliveCounter : 43|4@0+(1,0)[0|15] "" Vector__XXX
 SG_ VCU2HVILMajorLoop_@2WG3000 : 44|1@0+(1,0)[0|1] "" Vector__XXX
 SG_ VCU2DCDCEnabled : 45|1@0+(1,0)[0|1] "" Vector__XXX
 SG_ VCU2Checksum : 63|8@0+(1,0)[0|255] "" Vector__XXX
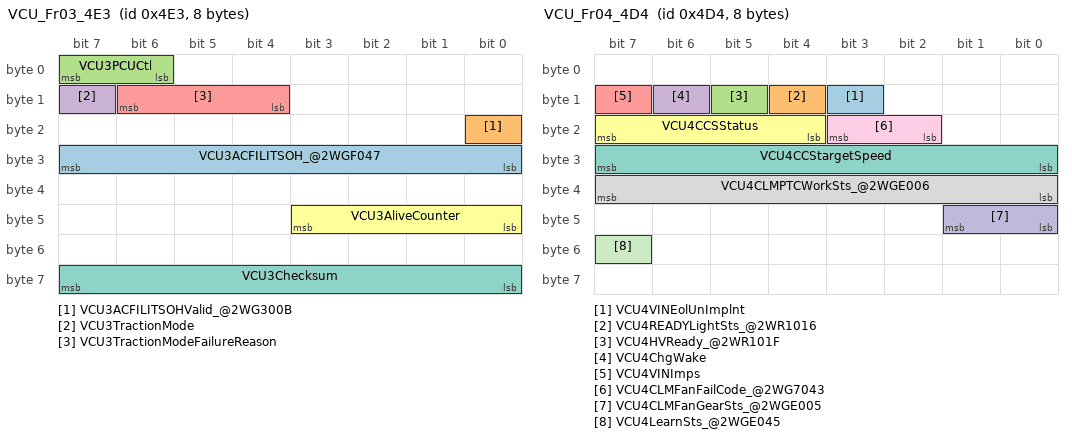
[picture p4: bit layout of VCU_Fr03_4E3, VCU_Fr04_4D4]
BO_ 1251 VCU_Fr03_4E3: 8 VCU1
 SG_ VCU3ACFILITSOH_@2WGF047 : 31|8@0+ (1,0) [0|0] "%"  TBOX
 SG_ VCU3ACFILITSOHValid_@2WG300B : 16|1@0+ (1,0) [0|0] ""  TBOX
 SG_ VCU3PCUCtl : 7|2@0+(1,0)[0|3] "" Vector__XXX
 SG_ VCU3TractionMode : 15|1@0+(1,0)[0|1] "" Vector__XXX
 SG_ VCU3TractionModeFailureReason : 14|3@0+(1,0)[0|7] "" Vector__XXX
 SG_ VCU3AliveCounter : 43|4@0+(1,0)[0|15] "" Vector__XXX
 SG_ VCU3Checksum : 63|8@0+(1,0)[0|255] "" Vector__XXX
BO_ 1236 VCU_Fr04_4D4: 8 VCU1
 SG_ VCU4VINEolUnImplnt : 11|1@0+(1,0)[0|1] "" Vector__XXX
 SG_ VCU4READYLightSts_@2WR1016 : 12|1@0+(1,0)[0|1] "" Vector__XXX
 SG_ VCU4HVReady_@2WR101F : 13|1@0+(1,0)[0|1] "" Vector__XXX
 SG_ VCU4ChgWake : 14|1@0+(1,0)[0|1] "" Vector__XXX
 SG_ VCU4VINImps : 15|1@0+(1,0)[0|1] "" Vector__XXX
 SG_ VCU4CCSStatus : 23|4@0+(1,0)[0|15] "" Vector__XXX
 SG_ VCU4CCStargetSpeed : 31|8@0+(1,0)[0|255] "Km/h" Vector__XXX
 SG_ VCU4CLMPTCWorkSts_@2WGE006 : 39|8@0+(1,0)[0|100] "%" Vector__XXX
 SG_ VCU4CLMFanFailCode_@2WG7043 : 19|2@0+(1,0)[0|3] "" Vector__XXX
 SG_ VCU4CLMFanGearSts_@2WGE005 : 41|2@0+(1,0)[0|3] "" Vector__XXX
 SG_ VCU4LearnSts_@2WGE045 : 55|1@0+(1,0)[0|1] "" Vector__XXX
BO_ 426 OBC_Fr01_1AA: 8 CDU
 SG_ OBC1CMState_@2WGE02E : 2|3@0+(1,0)[0|7] "" Vector__XXX
 SG_ OBC1ChargeCurrent_@2WGE02B : 15|16@0+(0.05,0)[0|400] "A" Vector__XXX
 SG_ OBC1ChargeVoltage_@2WGE02A : 31|16@0+(0.05,0)[0|1000] "V" Vector__XXX
 SG_ OBC1HighVolOutputUnderVol_@2WG7030 : 40|1@0+(1,0)[0|1] "" Vector__XXX
 SG_ OBC1HighVolOutputOverVol : 41|1@0+(1,0)[0|1] "" Vector__XXX
 SG_ OBC1HighVolOutputShortCircuit : 42|1@0+(1,0)[0|1] "" Vector__XXX
 SG_ OBC1InputUnderVoltage_@2WG702F : 43|1@0+(1,0)[0|1] "" Vector__XXX
 SG_ OBC1InputOverVoltage : 44|1@0+(1,0)[0|1] "" Vector__XXX
 SG_ OBC1OverTemperature : 46|2@0+(1,0)[0|3] "" Vector__XXX
 SG_ OBC1HighCurrentOutputFault : 52|1@0+(1,0)[0|1] "" Vector__XXX
 SG_ OBC1CANMsgFault : 53|1@0+(1,0)[0|1] "" Vector__XXX
 SG_ OBC1NoBattery : 7|1@0+(1,0)[0|1] "" Vector__XXX
 SG_ OBC1BatteryReverse : 54|1@0+(1,0)[0|1] "" Vector__XXX
 SG_ OBC1Temp : 63|8@0+(1,-48)[-48|206] "℃" Vector__XXX
 SG_ OBC1MsgCounter : 51|4@0+(1,0)[0|15] "" Vector__XXX
 SG_ CDU节点丢失_@2N003 : 51|4@0+(1,0)[0|15] "" Vector__XXX
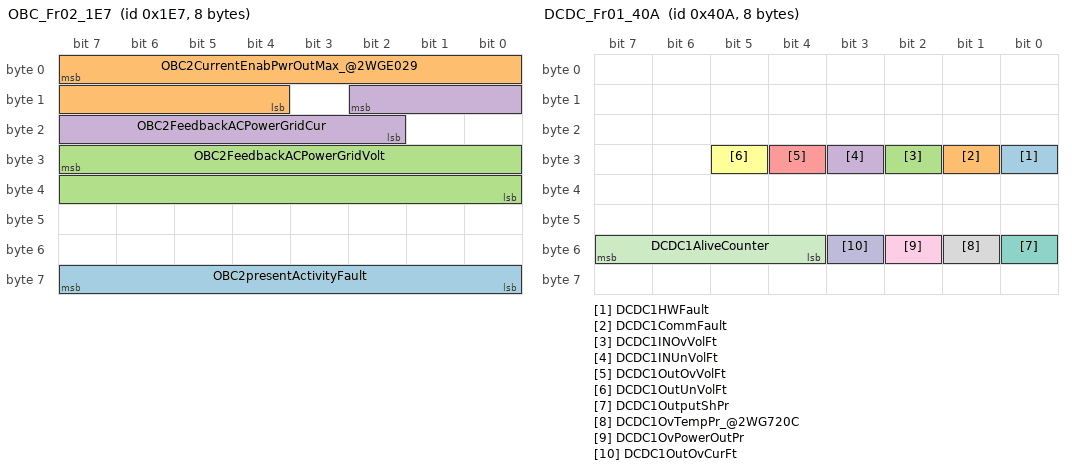
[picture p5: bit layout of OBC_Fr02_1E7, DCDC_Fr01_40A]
BO_ 487 OBC_Fr02_1E7: 8 CDU
 SG_ OBC2presentActivityFault : 63|8@0+(1,0)[0|128] "" Vector__XXX
 SG_ OBC2CurrentEnabPwrOutMax_@2WGE029 : 7|12@0+(0.005,0)[0|20.47] "KW" Vector__XXX
 SG_ OBC2FeedbackACPowerGridVolt : 31|16@0+(0.01,0)[0|655.34] "V" Vector__XXX
 SG_ OBC2FeedbackACPowerGridCur : 10|9@0+(0.1,0)[0|40] "A" Vector__XXX
BO_ 1433 OBC_Fr03_599: 8 CDU
 SG_ OBC3ChargeCurrentInp_@2WGE02C : 7|16@0+(0.05,0)[0|400] "A" Vector__XXX
 SG_ OBC3ChargeVoltageInp_@2WGE02D : 23|16@0+(0.05,0)[0|1000] "V" Vector__XXX
BO_ 1034 DCDC_Fr01_40A: 8 CDU
 SG_ DCDC1HWFault : 24|1@0+(1,0)[0|1] "" Vector__XXX
 SG_ DCDC1CommFault : 25|1@0+(1,0)[0|1] "" Vector__XXX
 SG_ DCDC1INOvVolFt : 26|1@0+(1,0)[0|1] "" Vector__XXX
 SG_ DCDC1INUnVolFt : 27|1@0+(1,0)[0|1] "" Vector__XXX
 SG_ DCDC1OutOvVolFt : 28|1@0+(1,0)[0|1] "" Vector__XXX
 SG_ DCDC1OutUnVolFt : 29|1@0+(1,0)[0|1] "" Vector__XXX
 SG_ DCDC1OutputShPr : 48|1@0+(1,0)[0|1] "" Vector__XXX
 SG_ DCDC1OvTempPr_@2WG720C : 49|1@0+(1,0)[0|1] "" Vector__XXX
 SG_ DCDC1OvPowerOutPr : 50|1@0+(1,0)[0|1] "" Vector__XXX
 SG_ DCDC1OutOvCurFt : 51|1@0+(1,0)[0|1] "" Vector__XXX
 SG_ DCDC1AliveCounter : 55|4@0+(1,0)[0|15] "" Vector__XXX
BO_ 1030 DCDC_Fr02_406: 8 CDU
 SG_ DCDC2InputVol : 7|14@0+(0.05,0)[0|819.1] "V" Vector__XXX
 SG_ DCDC2OutputVol : 9|10@0+(0.05,0)[0|51.15] "V" Vector__XXX
 SG_ DCDC2Temp : 31|8@0+(1,-48)[-48|206] "℃" Vector__XXX
 SG_ DCDC2InputCur : 39|8@0+(0.1,0)[0|25.4] "A" Vector__XXX
 SG_ DCDC2OutputCur : 47|12@0+(0.05,0)[0|204.7] "A" Vector__XXX
 SG_ DCDC2WorkState_@2WG1008 : 51|2@0+(1,0)[0|3] "" Vector__XXX
 SG_ WARNDCDC2WorkState_@2WG720E : 51|2@0+(1,0)[0|3] "" Vector__XXX
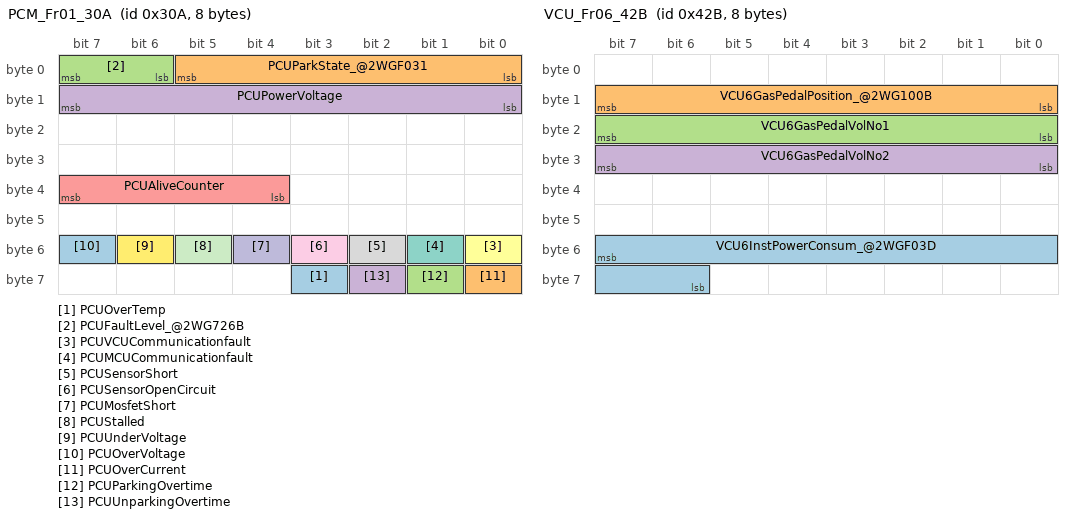
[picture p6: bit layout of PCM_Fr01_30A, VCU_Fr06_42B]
BO_ 778 PCM_Fr01_30A: 8 MCU
 SG_ PCUOverTemp : 59|1@0+(1,0)[0|1] "" Vector__XXX
 SG_ PCUParkState_@2WGF031 : 5|6@0+(1,0)[0|63] "" Vector__XXX
 SG_ PCUFaultLevel_@2WG726B : 7|2@0+(1,0)[0|3] "" Vector__XXX
 SG_ PCUPowerVoltage : 15|8@0+(1,0)[0|60] "V" Vector__XXX
 SG_ PCUAliveCounter : 39|4@0+(1,0)[0|15] "" Vector__XXX
 SG_ PCUVCUCommunicationfault : 48|1@0+(1,0)[0|1] "" Vector__XXX
 SG_ PCUMCUCommunicationfault : 49|1@0+(1,0)[0|1] "" Vector__XXX
 SG_ PCUSensorShort : 50|1@0+(1,0)[0|1] "" Vector__XXX
 SG_ PCUSensorOpenCircuit : 51|1@0+(1,0)[0|1] "" Vector__XXX
 SG_ PCUMosfetShort : 52|1@0+(1,0)[0|1] "" Vector__XXX
 SG_ PCUStalled : 53|1@0+(1,0)[0|1] "" Vector__XXX
 SG_ PCUUnderVoltage : 54|1@0+(1,0)[0|1] "" Vector__XXX
 SG_ PCUOverVoltage : 55|1@0+(1,0)[0|1] "" Vector__XXX
 SG_ PCUOverCurrent : 56|1@0+(1,0)[0|1] "" Vector__XXX
 SG_ PCUParkingOvertime : 57|1@0+(1,0)[0|1] "" Vector__XXX
 SG_ PCUUnparkingOvertime : 58|1@0+(1,0)[0|1] "" Vector__XXX
BO_ 547 VCU_Fr05_223: 8 VCU1
 SG_ VCU5GearboxPosDisplay_@2WG1009 : 3|4@0+(1,0)[0|15] "" Vector__XXX
 SG_ VCU5SystemWarningLightSts_@2WR1029 : 5|1@0+(1,0)[0|1] "" Vector__XXX
 SG_ EXTVCU5SystemWarningLightSts_@2WG7265 : 5|1@0+(1,0)[0|1] "" Vector__XXX
 SG_ VCU5EnergyRecLevelSts : 7|2@0+(1,0)[0|3] "" Vector__XXX
 SG_ VCU5PNLelFault_@2WG7233 : 8|1@0+(1,0)[0|1] "" Vector__XXX
 SG_ ExtVCU5PNLelFault_@2WG7234 : 8|1@0+(1,0)[0|1] "" Vector__XXX
 SG_ VCU5SOCWarningLightSts_@2WG723D : 11|1@0+(1,0)[0|1] "" Vector__XXX
 SG_ VCU5BatElecDisFtWarnLtSt_@2WG7020 : 13|1@0+(1,0)[0|1] "" Vector__XXX
 SG_ VCU5SysFaultsWarnLtSts_@2WR1021 : 14|1@0+(1,0)[0|1] "" Vector__XXX
 SG_ EXTVCU5SysFaultsWarnLtSts_@2WG725C : 14|1@0+(1,0)[0|1] "" Vector__XXX
 SG_ VCU5AuthStatus : 19|2@0+(1,0)[0|3] "" Vector__XXX
 SG_ VCU5ResidualOdometer_@2WGF02F : 31|16@0+(1,0)[0|1024] "Km" Vector__XXX
 SG_ VCU5LBattVoltage : 55|8@0+(0.1,0)[0|18] "V" Vector__XXX
 SG_ VCU5InstPowerConsum : 63|8@0+(0.1,0)[0|25] "KW/h" Vector__XXX
 SG_ VCU5DriveMode_@2WGF030 : 23|2@0+(1,0)[0|3] "" Vector__XXX
BO_ 1067 VCU_Fr06_42B: 8 VCU1
 SG_ VCU6InstPowerConsum_@2WGF03D : 55|10@0+ (1,-500) [-500|500] ""  TBOX
 SG_ VCU6GasPedalPosition_@2WG100B : 15|8@0+(1,0)[0|100] "%" Vector__XXX
 SG_ VCU6GasPedalVolNo1 : 23|8@0+(0.1,0)[0|22.5] "v" Vector__XXX
 SG_ VCU6GasPedalVolNo2 : 31|8@0+(0.1,0)[0|22.5] "v" Vector__XXX
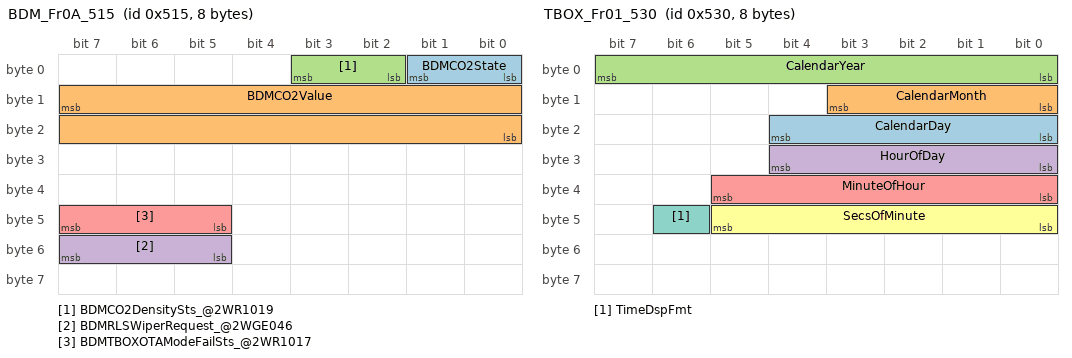
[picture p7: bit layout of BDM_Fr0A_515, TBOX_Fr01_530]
BO_ 1301 BDM_Fr0A_515: 8 BDCM
 SG_ BDMCO2State : 1|2@0+(1,0)[0|3] "" Vector__XXX
 SG_ BDMCO2Value : 15|16@0+(1,0)[0|5000] "ug/m3" Vector__XXX
 SG_ BDMCO2DensitySts_@2WR1019 : 3|2@0+(1,0)[0|3] "" Vector__XXX
 SG_ BDMRLSWiperRequest_@2WGE046 : 55|3@0+(1,0)[0|7] "" Vector__XXX
 SG_ BDMTBOXOTAModeFailSts_@2WR1017 : 47|3@0+(1,0)[0|7] "" Vector__XXX
BO_ 1328 TBOX_Fr01_530: 8 TBOX
 SG_ CalendarDay : 20|5@0+(1,0)[0|31] "days" Vector__XXX
 SG_ CalendarMonth : 11|4@0+(1,0)[0|15] "" Vector__XXX
 SG_ CalendarYear : 7|8@0+(1,2000)[2000|2255] "year" Vector__XXX
 SG_ HourOfDay : 28|5@0+(1,0)[0|23] "" Vector__XXX
 SG_ MinuteOfHour : 37|6@0+(1,0)[0|59] "" Vector__XXX
 SG_ SecsOfMinute : 45|6@0+(1,0)[0|59] "" Vector__XXX
 SG_ TimeDspFmt : 46|1@0+(1,0)[0|1] "" Vector__XXX
BO_ 1088 TBOX_Fr03_440: 8 TBOX
 SG_ TBOXBluetoothStartReq : 40|1@0+ (1,0) [0|0] "" Vector__XXX
 SG_ TBOXRemoteStartReq : 0|1@0+(1,0)[0|1] "" Vector__XXX
 SG_ TBOXRemoteShutdownReq : 1|1@0+(1,0)[0|1] "" Vector__XXX
 SG_ TBOXStartForbidReq : 31|2@0+(1,0)[0|3] "" Vector__XXX
 SG_ TBOXChargeCmd : 3|2@0+(1,0)[0|2] "" Vector__XXX
 SG_ TBOXChargeAppointmentSet : 4|1@0+(1,0)[0|1] "" Vector__XXX
 SG_ TBOXChargeAppointmentTimeSet : 15|8@0+(10,0)[0|1440] "min" Vector__XXX
 SG_ TBOXRemoteLockCtrl : 17|2@0+(1,0)[0|3] "" Vector__XXX
 SG_ TBOXRemoteTrunkCtrl : 19|2@0+(1,0)[0|3] "" Vector__XXX
 SG_ TBOXFLWindowsCtrl : 7|3@0+(1,0)[0|7] "" Vector__XXX
 SG_ TBOXFRWindowsCtrl : 22|3@0+(1,0)[0|7] "" Vector__XXX
 SG_ TBOXRLWindowsCtrl : 26|3@0+(1,0)[0|7] "" Vector__XXX
 SG_ TBOXRRWindowsCtrl : 29|3@0+(1,0)[0|7] "" Vector__XXX
 SG_ TBOXRemoteSunroofCtrl : 47|3@0+(1,0)[0|7] "" Vector__XXX
 SG_ TBOXRemoteSunshadeCtrl : 33|2@0+(1,0)[0|3] "" Vector__XXX
 SG_ TBOXDVRRemotePhotoCtrl : 34|1@0+(1,0)[0|1] "" Vector__XXX
 SG_ TBOXDVRRemoteRecordCtrl : 35|1@0+(1,0)[0|1] "" Vector__XXX
 SG_ TBOXIRSRemotePhotoCtrl : 36|1@0+(1,0)[0|1] "" Vector__XXX
 SG_ TBOXIRSRemoteRecordCtrl : 37|1@0+(1,0)[0|1] "" Vector__XXX
 SG_ TBOXBDMOTAModeReq : 39|2@0+(1,0)[0|3] "" Vector__XXX
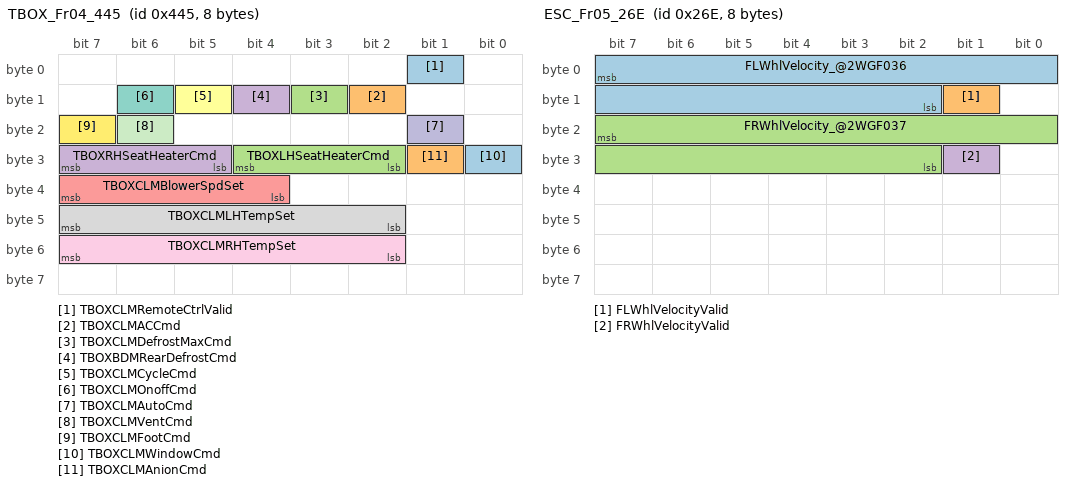
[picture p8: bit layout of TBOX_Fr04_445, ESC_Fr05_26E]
BO_ 1093 TBOX_Fr04_445: 8 TBOX
 SG_ TBOXCLMRemoteCtrlValid : 1|1@0+(1,0)[0|1] "" Vector__XXX
 SG_ TBOXCLMACCmd : 10|1@0+(1,0)[0|1] "" Vector__XXX
 SG_ TBOXCLMDefrostMaxCmd : 11|1@0+(1,0)[0|1] "" Vector__XXX
 SG_ TBOXBDMRearDefrostCmd : 12|1@0+(1,0)[0|1] "" Vector__XXX
 SG_ TBOXCLMBlowerSpdSet : 39|4@0+(1,0)[0|15] "" Vector__XXX
 SG_ TBOXCLMCycleCmd : 13|1@0+(1,0)[0|1] "" Vector__XXX
 SG_ TBOXCLMOnoffCmd : 14|1@0+(1,0)[0|1] "" Vector__XXX
 SG_ TBOXCLMLHTempSet : 47|6@0+(0.5,16)[16|32] "" Vector__XXX
 SG_ TBOXCLMRHTempSet : 55|6@0+(0.5,16)[16|32] "" Vector__XXX
 SG_ TBOXCLMAutoCmd : 17|1@0+(1,0)[0|1] "" Vector__XXX
 SG_ TBOXCLMVentCmd : 22|1@0+(1,0)[0|1] "" Vector__XXX
 SG_ TBOXCLMFootCmd : 23|1@0+(1,0)[0|1] "" Vector__XXX
 SG_ TBOXCLMWindowCmd : 24|1@0+(1,0)[0|1] "" Vector__XXX
 SG_ TBOXCLMAnionCmd : 25|1@0+(1,0)[0|1] "" Vector__XXX
 SG_ TBOXLHSeatHeaterCmd : 28|3@0+(1,0)[0|4] "" Vector__XXX
 SG_ TBOXRHSeatHeaterCmd : 31|3@0+(1,0)[0|4] "" Vector__XXX
BO_ 454 EHB_Fr01_1C6: 8 EHB
 SG_ BrakePedalApplied_@2WG100C : 23|1@0+(1,0)[0|1] "" Vector__XXX
 SG_ BrakePedalAppliedV_@2WG3005 : 5|1@0+(1,0)[0|1] "" Vector__XXX
 SG_ EHB节点丢失_@2N008 : 5|1@0+(1,0)[0|1] "" Vector__XXX
BO_ 456 EHB_Fr02_1C8: 8 EHB
 SG_ BrakPedalDisp : 31|16@0+(0.0078125,0)[0|200] "mm" Vector__XXX
 SG_ BrakPedalDispQ_@2WG3006 : 1|1@0+(1,0)[0|1] "" Vector__XXX
 SG_ EHBFr02MsgCounter : 55|4@0+(1,0)[0|15] "" Vector__XXX
 SG_ EHBFr02Checksum : 63|8@0+(1,0)[0|255] "" Vector__XXX
 SG_ EHBFailedState_@2WR102B : 2|1@0+ (1,0) [0|1] ""  VCU,MCU,ESC,ICU
 SG_ EXTEHBFailedState_@2WG715F : 2|1@0+ (1,0) [0|1] ""  VCU,MCU,ESC,ICU
BO_ 229 ESC_Fr01_0E5: 8 ESC
 SG_ ExtABSFail_@2WG7248 : 6|1@0+(1,0)[0|1] "" Vector__XXX
 SG_ EBDFail : 5|1@0+(1,0)[0|1] "" Vector__XXX
 SG_ ESCActive_@2WGF040 : 3|1@0+(1,0)[0|1] "" Vector__XXX
 SG_ ESCDisable_@2WGF041 : 2|1@0+(1,0)[0|1] "" Vector__XXX
 SG_ ESCStatusLampReq : 14|2@0+(1,0)[0|3] "" Vector__XXX
 SG_ ESCBrakeWarnLamp_@2WR1027 : 18|2@0+(1,0)[0|3] "" Vector__XXX
 SG_ GBESCBrakeWarnLamp_@2WG720D : 18|2@0+(1,0)[0|3] "" Vector__XXX
 SG_ ESCWarningLamp : 9|1@0+(1,0)[0|1] "" Vector__XXX
 SG_ TCSActive_@2WGF042 : 8|1@0+(1,0)[0|1] "" Vector__XXX
 SG_ TCSFail : 22|1@0+(1,0)[0|1] "" Vector__XXX
 SG_ ESC节点丢失_@2N007 : 22|1@0+(1,0)[0|1] "" Vector__XXX
BO_ 622 ESC_Fr05_26E: 8 ESC
 SG_ FLWhlVelocity_@2WGF036 : 7|14@0+(0.03125,0)[0|511.9375] "km/h" Vector__XXX
 SG_ FLWhlVelocityValid : 9|1@0+(1,0)[0|1] "" Vector__XXX
 SG_ FRWhlVelocity_@2WGF037 : 23|14@0+(0.03125,0)[0|511.9375] "km/h" Vector__XXX
 SG_ FRWhlVelocityValid : 25|1@0+(1,0)[0|1] "" Vector__XXX
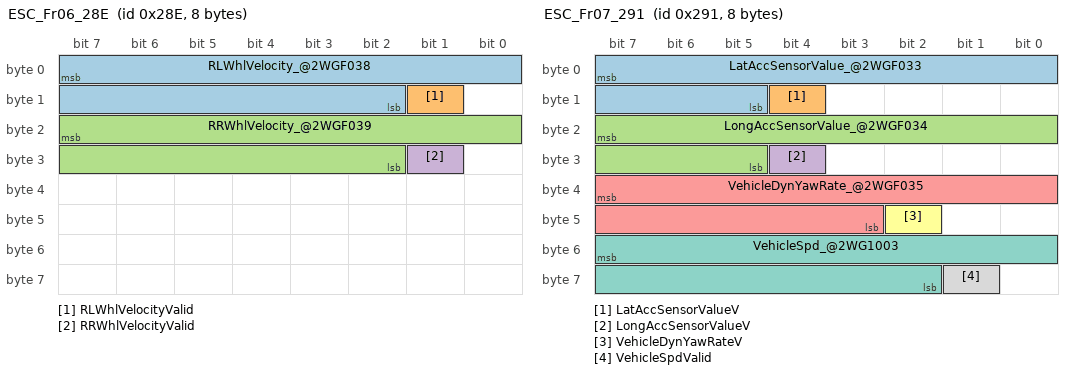
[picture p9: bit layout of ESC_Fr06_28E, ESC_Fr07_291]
BO_ 654 ESC_Fr06_28E: 8 ESC
 SG_ RLWhlVelocity_@2WGF038 : 7|14@0+(0.03125,0)[0|511.9375] "km/h" Vector__XXX
 SG_ RLWhlVelocityValid : 9|1@0+(1,0)[0|1] "" Vector__XXX
 SG_ RRWhlVelocity_@2WGF039 : 23|14@0+(0.03125,0)[0|511.9375] "km/h" Vector__XXX
 SG_ RRWhlVelocityValid : 25|1@0+(1,0)[0|1] "" Vector__XXX
BO_ 657 ESC_Fr07_291: 8 ESC
 SG_ LatAccSensorValue_@2WGF033 : 7|11@0+(0.01,-10.23)[-10.23|10.23] "m/s^2" Vector__XXX
 SG_ LatAccSensorValueV : 12|1@0+(1,0)[0|1] "" Vector__XXX
 SG_ LongAccSensorValue_@2WGF034 : 23|11@0+(0.01,-10.23)[-10.23|10.23] "m/s^2" Vector__XXX
 SG_ LongAccSensorValueV : 28|1@0+(1,0)[0|1] "" Vector__XXX
 SG_ VehicleDynYawRate_@2WGF035 : 39|13@0+(0.01,-40.95)[-40.95|40.95] "deg/sec" Vector__XXX
 SG_ VehicleDynYawRateV : 42|1@0+(1,0)[0|1] "" Vector__XXX
 SG_ VehicleSpd_@2WG1003 : 55|14@0+(0.03125,0)[0|511.9375] "km/h" Vector__XXX
 SG_ VehicleSpdValid : 57|1@0+(1,0)[0|1] "" Vector__XXX
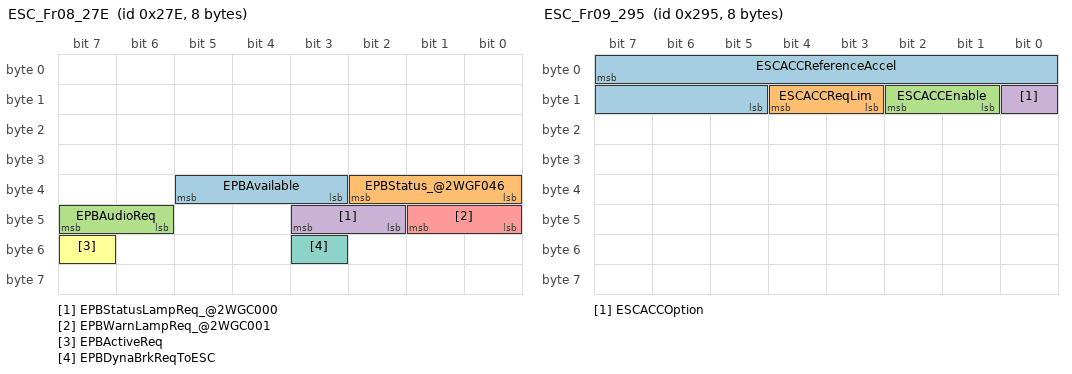
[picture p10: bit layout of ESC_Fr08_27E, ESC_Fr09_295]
BO_ 638 ESC_Fr08_27E: 8 ESC
 SG_ EPBAvailable : 37|3@0+(1,0)[0|7] "" Vector__XXX
 SG_ EPBStatus_@2WGF046 : 34|3@0+(1,0)[0|7] "" Vector__XXX
 SG_ EPBAudioReq : 47|2@0+(1,0)[0|3] "" Vector__XXX
 SG_ EPBStatusLampReq_@2WGC000 : 43|2@0+(1,0)[0|3] "" Vector__XXX
 SG_ EPBWarnLampReq_@2WGC001 : 41|2@0+(1,0)[0|3] "" Vector__XXX
 SG_ EPBActiveReq : 55|1@0+(1,0)[0|1] "" Vector__XXX
 SG_ EPBDynaBrkReqToESC : 51|1@0+(1,0)[0|1] "" Vector__XXX
BO_ 661 ESC_Fr09_295: 8 ESC
 SG_ ESCACCReferenceAccel : 7|11@0+(0.01,-10.23)[-10.23|10.24] "m/s^2" Vector__XXX
 SG_ ESCACCReqLim : 12|2@0+(1,0)[0|3] "" Vector__XXX
 SG_ ESCACCEnable : 10|2@0+(1,0)[0|3] "" Vector__XXX
 SG_ ESCACCOption : 8|1@0+(1,0)[0|1] "" Vector__XXX
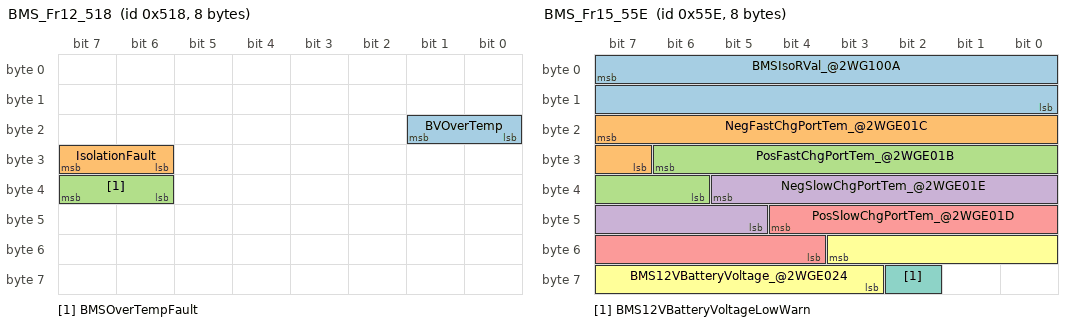
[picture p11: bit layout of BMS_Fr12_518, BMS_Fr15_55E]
BO_ 1304 BMS_Fr12_518: 8 BMS
 SG_ BVOverTemp : 17|2@0+(1,0)[0|3] "" Vector__XXX
 SG_ IsolationFault : 31|2@0+(1,0)[0|3] "" Vector__XXX
 SG_ BMSOverTempFault : 39|2@0+(1,0)[0|3] "" Vector__XXX
BO_ 1374 BMS_Fr15_55E: 8 BMS
 SG_ BMSIsoRVal_@2WG100A : 7|16@0+(1,0)[0|60000] "ΚΩ" Vector__XXX
 SG_ NegFastChgPortTem_@2WGE01C : 23|9@0+(1,-40)[-40|300] "℃" Vector__XXX
 SG_ PosFastChgPortTem_@2WGE01B : 30|9@0+(1,-40)[-40|300] "℃" Vector__XXX
 SG_ NegSlowChgPortTem_@2WGE01E : 37|9@0+(1,-40)[-40|300] "℃" Vector__XXX
 SG_ PosSlowChgPortTem_@2WGE01D : 44|9@0+(1,-40)[-40|300] "℃" Vector__XXX
 SG_ BMS12VBatteryVoltage_@2WGE024 : 51|9@0+(0.05,0)[0|25] "V" Vector__XXX
 SG_ BMS12VBatteryVoltageLowWarn : 58|1@0+(1,0)[0|1] "" Vector__XXX
BO_ 1952 DIAGPhysReqTBOX: 8 Tester
 SG_ DiagnosticReqTBOX : 7|64@0+(1,0)[0|0] "" Vector__XXX
BO_ 1968 DIAGPhysRespTBOX: 8 TBOX
 SG_ DiagnosticRespTBOX : 7|64@0+(1,0)[0|0] "" Vector__XXX
BO_ 2015 DIAG_FuncReq_7DF: 8 Tester
 SG_ DiagnosticFuncAddrReq : 7|64@0+(1,0)[0|0] "" Vector__XXX
BO_ 1013 IHU_Fr02_3F5: 8 IHU
 SG_ IHUChargeCmd : 33|1@0+(1,0)[0|1] "" Vector__XXX
 SG_ IHUChargeAppointmentSet : 32|1@0+(1,0)[0|1] "" Vector__XXX
 SG_ IHUChargeAppointmentTimeSet : 47|8@0+(10,0)[0|1440] "min" Vector__XXX
 SG_ IHU节点丢失_@2N016 : 47|8@0+(10,0)[0|1440] "min" Vector__XXX
BO_ 1032 PLG_Fr01_408: 8 PLG
 SG_ PLGRearDoorStatus_@2WGF00E : 2|3@0+(1,0)[0|3] "" Vector__XXX
 SG_ PLG节点丢失_@2N011 : 2|3@0+(1,0)[0|3] "" Vector__XXX
BO_ 853 PTC_Fr01_355: 8 PTC
 SG_ PTCPowerConsumption_@2WGE040 : 31|8@0+(0.1,0)[0|25.3] "kw" Vector__XXX
 SG_ PTCClntTempInlt_@2WGE041 : 47|8@0+(1,-40)[-40|100] "℃" Vector__XXX
 SG_ PTCClntTempOtlt_@2WGE042 : 55|8@0+(1,-40)[-40|100] "℃" Vector__XXX
 SG_ PTCWrkngSts_@2WGE038 : 7|2@0+(1,0)[0|3] "" Vector__XXX
 SG_ PTC节点丢失_@2N010 : 7|2@0+(1,0)[0|3] "" Vector__XXX
BO_ 885 EAC_Fr01_375: 8 EACP
 SG_ EACACPSpeed_@2WGE03E : 31|7@0+(100,0)[0|8600] "rpm" Vector__XXX
 SG_ EACBaseState_@2WGE03C : 54|3@0+(1,0)[0|7] "" Vector__XXX
 SG_ EACInputVolt_@2WGE03F : 8|9@0+(1,0)[0|510] "v" Vector__XXX
 SG_ EACP节点丢失_@2N009 : 8|9@0+(1,0)[0|510] "v" Vector__XXX
BO_ 917 CLM_Fr01_395: 8 CLM
 SG_ CLMEACSpeedSet_@2WGE03D : 17|7@0+(100,0)[0|8600] "rpm" Vector__XXX
 SG_ CLM节点丢失_@2N012 : 17|7@0+(100,0)[0|8600] "rpm" Vector__XXX
BO_ 926 CLM_Fr02_39E: 8 CLM
 SG_ CLMACSts_@2WGE037 : 0|1@0+(1,0)[0|1] "" Vector__XXX
 SG_ CLMDefrostMaxSts : 1|1@0+(1,0)[0|1] "" Vector__XXX
 SG_ CLMCycleSts_@2WGE031 : 3|2@0+(1,0)[0|3] "" Vector__XXX
 SG_ CLMOnOffSts_@2WGF00F : 8|1@0+(1,0)[0|1] "" Vector__XXX
 SG_ CLMBlowerSpdSts_@2WGF012 : 7|4@0+(1,0)[0|15] "" Vector__XXX
 SG_ CLMAutoSts_@2WR101D : 38|1@0+ (1,0) [0|1] "" Vector__XXX
 SG_ GBCLMAutoSts_@2WG300A : 38|1@0+ (1,0) [0|1] "" Vector__XXX
 SG_ CLMLHTemp_@2WGE035 : 14|6@0+(0.5,16)[16|32] "" Vector__XXX
 SG_ CLMRHTemp_@2WGE036 : 21|6@0+(0.5,16)[16|32] "" Vector__XXX
 SG_ CLMVentSts_@2WGE032 : 15|1@0+(1,0)[0|1] "" Vector__XXX
 SG_ CLMFootSts_@2WGE033 : 39|1@0+ (1,0) [0|1] "" Vector__XXX
 SG_ CLMWindowSts_@2WGE034 : 22|1@0+(1,0)[0|1] "" Vector__XXX
 SG_ CLMAnionSts : 23|1@0+(1,0)[0|1] "" Vector__XXX
 SG_ CLMPM25ValueValid_@2WR1018 : 32|1@0+(1,0)[0|1] "" Vector__XXX
 SG_ CLMPM25Value : 31|8@0+(4,0)[0|1020] "" Vector__XXX
 SG_ CLMOutsideTempValid_@2WG3002 : 33|1@0+(1,0)[0|1] "" Vector__XXX
 SG_ CLMOutsideTemp_@2WGF014 : 47|8@0+(0.5,-50)[-50|75] "℃" Vector__XXX
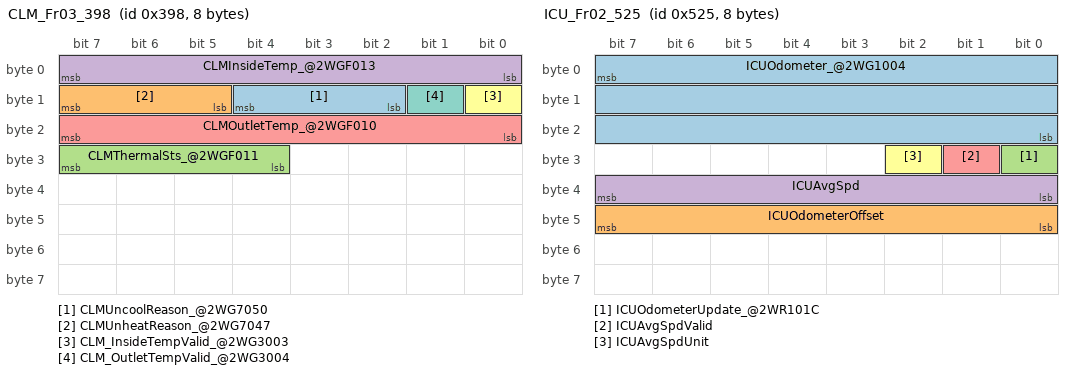
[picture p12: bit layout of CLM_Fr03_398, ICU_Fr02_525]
BO_ 920 CLM_Fr03_398: 8 CLM
 SG_ CLMUncoolReason_@2WG7050 : 12|3@0+(1,0)[0|7] "" Vector__XXX
 SG_ CLMUnheatReason_@2WG7047 : 15|3@0+(1,0)[0|7] "" Vector__XXX
 SG_ CLMThermalSts_@2WGF011 : 31|4@0+(1,0)[0|15] "" Vector__XXX
 SG_ CLMInsideTemp_@2WGF013 : 7|8@0+(0.5,-50)[-50|75] "" Vector__XXX
 SG_ CLMOutletTemp_@2WGF010 : 23|8@0+(0.5,-50)[-50|75] "" Vector__XXX
 SG_ CLM_InsideTempValid_@2WG3003 : 8|1@0+ (1,0) [0|1] ""  Vector__XXX
 SG_ CLM_OutletTempValid_@2WG3004 : 9|1@0+ (1,0) [0|1] ""  Vector__XXX
BO_ 542 ICU_Fr01_21E: 8 ICU
 SG_ ICUBrakeFluidLow_@2WG724A : 10|1@0+(1,0)[0|1] "" Vector__XXX
 SG_ ICU节点丢失_@2N015 : 10|1@0+(1,0)[0|1] "" Vector__XXX
BO_ 1317 ICU_Fr02_525: 8 ICU
 SG_ ICUOdometer_@2WG1004 : 7|24@0+(0.1,0)[0|1677721.4] "km" Vector__XXX
 SG_ ICUOdometerOffset : 47|8@0+(1,0)[0|255] "km" Vector__XXX
 SG_ ICUOdometerUpdate_@2WR101C : 24|1@0+(1,0)[0|1] "" Vector__XXX
 SG_ ICUAvgSpd : 39|8@0+(1,0)[0|255] "kph
mph" Vector__XXX
 SG_ ICUAvgSpdValid : 25|1@0+(1,0)[0|1] "" Vector__XXX
 SG_ ICUAvgSpdUnit : 26|1@0+(1,0)[0|1] "" Vector__XXX
BO_ 1318 TBOX_Fr05_526: 8 TBOX
 SG_ TBOXOdometer : 7|24@0+(0.1,0)[0|1677721.4] "km" Vector__XXX
BO_ 1319 BDM_Fr0B_527: 8 BDCM
 SG_ BDMOdometer : 7|24@0+(0.1,0)[0|1677721.4] "km" Vector__XXX
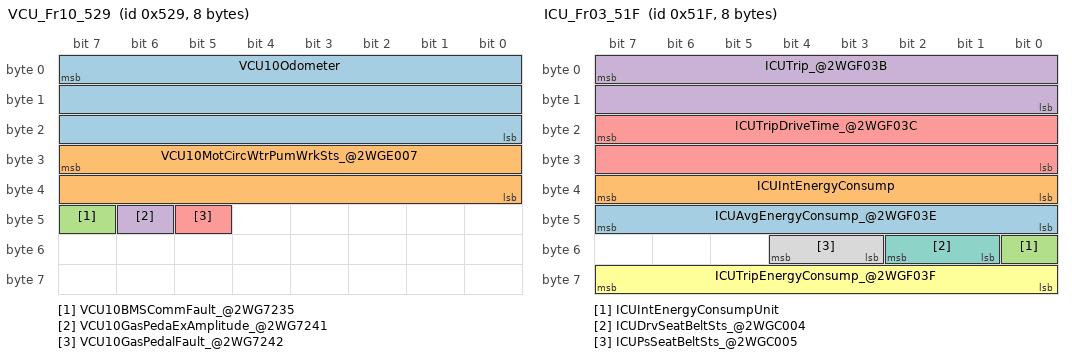
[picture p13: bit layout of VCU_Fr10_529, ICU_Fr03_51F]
BO_ 1321 VCU_Fr10_529: 8 VCU1
 SG_ VCU10Odometer : 7|24@0+(0.1,0)[0|1677721.4] "km" Vector__XXX
 SG_ VCU10MotCircWtrPumWrkSts_@2WGE007 : 31|16@0+(0.1,0)[0|100] "%" Vector__XXX
 SG_ VCU10BMSCommFault_@2WG7235 : 47|1@0+(1,0)[0|1] "" Vector__XXX
 SG_ VCU10GasPedaExAmplitude_@2WG7241 : 46|1@0+(1,0)[0|1] "" Vector__XXX
 SG_ VCU10GasPedalFault_@2WG7242 : 45|1@0+(1,0)[0|1] "" Vector__XXX
BO_ 1311 ICU_Fr03_51F: 8 ICU
 SG_ ICUAvgEnergyConsump_@2WGF03E : 47|8@0+(0.1,0)[0|25.5] "kwh/100km" Vector__XXX
 SG_ ICUIntEnergyConsump : 39|8@0+(0.1,0)[0|25.5] "kwh/100km
 kwh/h" Vector__XXX
 SG_ ICUIntEnergyConsumpUnit : 48|1@0+(1,0)[0|1] "" Vector__XXX
 SG_ ICUTrip_@2WGF03B : 7|16@0+(1,0)[0|65535] "km" Vector__XXX
 SG_ ICUTripDriveTime_@2WGF03C : 23|16@0+(1,0)[0|65535] "s" Vector__XXX
 SG_ ICUTripEnergyConsump_@2WGF03F : 63|8@0+(0.1,0)[0|25.5] "kwh/100km" Vector__XXX
 SG_ ICUDrvSeatBeltSts_@2WGC004 : 50|2@0+(1,0)[0|3] "" Vector__XXX
 SG_ ICUPsSeatBeltSts_@2WGC005 : 52|2@0+(1,0)[0|3] "" Vector__XXX
BO_ 1298 TAP_Fr01_512: 8 TAP
 SG_ TAPSystemStatus : 7|3@0+(1,0)[0|7] "" Vector__XXX
 SG_ TAP节点丢失_@2N017 : 7|3@0+(1,0)[0|7] "" Vector__XXX
BO_ 1326 TAP_Fr02_52E: 8 TAP
 SG_ TapUpgradeResult : 2|3@0+(1,0)[0|7] "" Vector__XXX
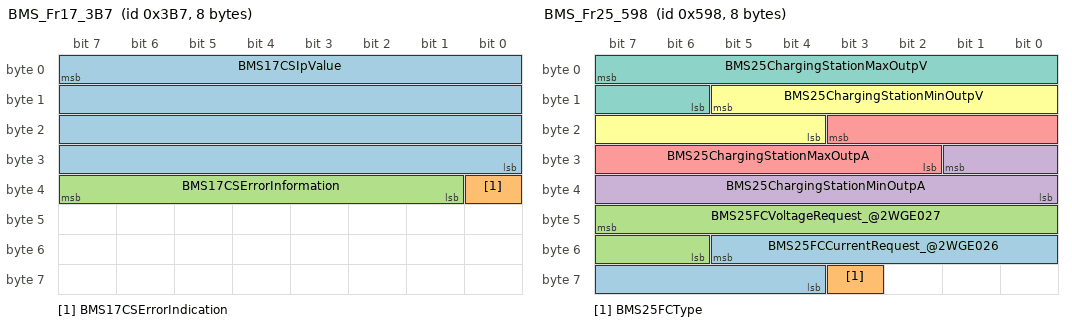
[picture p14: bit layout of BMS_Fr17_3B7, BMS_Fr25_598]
BO_ 951 BMS_Fr17_3B7: 8 BMS
 SG_ BMS17CSIpValue : 7|32@0+(1,-2147483648)[0|1] "mA" Vector__XXX
 SG_ BMS17CSErrorIndication : 32|1@0+(1,0)[0|1] "" Vector__XXX
 SG_ BMS17CSErrorInformation : 39|7@0+(1,0)[0|127] "" Vector__XXX
BO_ 912 ALM_Fr01_390: 8 ALM
 SG_ ALMIHUBrightnessfeedback : 7|8@0+(1,0)[0|100] "%" Vector__XXX
 SG_ ALMIHURvaluefeedback : 15|8@0+(1,0)[0|255] "" Vector__XXX
 SG_ ALMIHUGvaluefeedback : 23|8@0+(1,0)[0|255] "" Vector__XXX
 SG_ ALMIHUBvaluefeedback : 31|8@0+(1,0)[0|255] "" Vector__XXX
 SG_ ALMIHUfeedback_@2WGF01C : 36|1@0+(1,0)[0|1] "" Vector__XXX
 SG_ ALM节点丢失_@2N014 : 36|1@0+(1,0)[0|1] "" Vector__XXX
BO_ 1430 BMS_Fr23_596: 8 BMS
 SG_ BMS58HdsahTotalCpSum_@2WGE022 : 39|25@0+(0.01,0)[0|210240] "Ah" Vector__XXX
BO_ 1431 BMS_Fr24_597: 8 BMS
 SG_ BMS24HdsahReActiveCpSum : 7|25@0+(0.01,0)[0|210240] "Ah" Vector__XXX
 SG_ BMS24HdsahActiveCpSum_@2WGE023 : 30|25@0+(0.01,0)[0|210240] "Ah" Vector__XXX
BO_ 1432 BMS_Fr25_598: 8 BMS
 SG_ BMS25FCCurrentRequest_@2WGE026 : 53|10@0+ (1,-400) [-400|400] "A"  Vector__XXX
 SG_ BMS25FCType : 59|1@0+ (1,0) [0|1] ""  Vector__XXX
 SG_ BMS25FCVoltageRequest_@2WGE027 : 47|10@0+ (1,0) [0|1000] "V"  Vector__XXX
 SG_ BMS25ChargingStationMinOutpA : 25|10@0+ (1,-400) [-400|400] "A"  Vector__XXX
 SG_ BMS25ChargingStationMaxOutpA : 19|10@0+ (1,-400) [-400|400] "A"  Vector__XXX
 SG_ BMS25ChargingStationMinOutpV : 13|10@0+ (1,0) [0|1000] "V"  Vector__XXX
 SG_ BMS25ChargingStationMaxOutpV : 7|10@0+ (1,0) [0|1000] "V"  Vector__XXX
BO_ 1537 TBOXNM601: 8 TBOX
 SG_ TBOXSourceNodeIdentifier : 7|8@0+(1,0)[0|255] "" Vector__XXX
 SG_ TBOXRepeatMessageRequest : 8|1@0+(1,0)[0|1] "" Vector__XXX
 SG_ TBOXReserve1 : 11|3@0+(1,0)[0|3] "" Vector__XXX
 SG_ TBOXActiveWakeup : 12|1@0+(1,0)[0|1] "" Vector__XXX
 SG_ TBOXReserve2 : 15|3@0+(1,0)[0|7] "" Vector__XXX
 SG_ TBOXWakeUpReason1 : 16|1@0+(1,0)[0|1] "" Vector__XXX
 SG_ TBOXWakeUpReason2 : 17|1@0+(1,0)[0|1] "" Vector__XXX
 SG_ TBOXWakeUpReason3 : 18|1@0+(1,0)[0|1] "" Vector__XXX
 SG_ TBOXWakeUpReason4 : 19|1@0+(1,0)[0|1] "" Vector__XXX
 SG_ TBOXWakeUpReason5 : 20|1@0+(1,0)[0|1] "" Vector__XXX
 SG_ TBOXWakeUpReason6 : 21|1@0+(1,0)[0|1] "" Vector__XXX
 SG_ TBOXWakeUpReason7 : 22|1@0+(1,0)[0|1] "" Vector__XXX
 SG_ TBOXWakeUpReason8 : 23|1@0+(1,0)[0|1] "" Vector__XXX
 SG_ TBOXRepeatFromSleep : 24|1@0+(1,0)[0|1] "" Vector__XXX
 SG_ TBOXRepeatFromPrepare : 25|1@0+(1,0)[0|1] "" Vector__XXX
 SG_ TBOXRepeatFromNormal : 26|1@0+(1,0)[0|1] "" Vector__XXX
 SG_ TBOXRepeatFromReady : 27|1@0+(1,0)[0|1] "" Vector__XXX
 SG_ TBOXNormalFromRepeat : 28|1@0+(1,0)[0|1] "" Vector__XXX
 SG_ TBOXNormalFromReady : 29|1@0+(1,0)[0|1] "" Vector__XXX
 SG_ TBOXRemainNetworkWakeUpReason1 : 32|1@0+(1,0)[0|1] "" Vector__XXX
 SG_ TBOXRemainNetworkWakeUpReason2 : 33|1@0+(1,0)[0|1] "" Vector__XXX
 SG_ TBOXRemainNetworkWakeUpReason3 : 34|1@0+(1,0)[0|1] "" Vector__XXX
 SG_ TBOXRemainNetworkWakeUpReason4 : 35|1@0+(1,0)[0|1] "" Vector__XXX
 SG_ TBOXRemainNetworkWakeUpReason5 : 36|1@0+(1,0)[0|1] "" Vector__XXX
 SG_ TBOXRemainNetworkWakeUpReason6 : 37|1@0+(1,0)[0|1] "" Vector__XXX
 SG_ TBOXRemainNetworkWakeUpReason7 : 38|1@0+(1,0)[0|1] "" Vector__XXX
 SG_ TBOXRemainNetworkWakeUpReason8 : 39|1@0+(1,0)[0|1] "" Vector__XXX
 SG_ TBOXRemainNetworkWakeUpReason9 : 40|1@0+(1,0)[0|1] "" Vector__XXX
 SG_ TBOXRemainNetworkWakeUpReason10 : 41|1@0+(1,0)[0|1] "" Vector__XXX
 SG_ TBOXRemainNetworkWakeUpReason11 : 42|1@0+(1,0)[0|1] "" Vector__XXX
 SG_ TBOXRemainNetworkWakeUpReason12 : 43|1@0+(1,0)[0|1] "" Vector__XXX
 SG_ TBOXRemainNetworkWakeUpReason13 : 44|1@0+(1,0)[0|1] "" Vector__XXX
 SG_ TBOXRemainNetworkWakeUpReason14 : 45|1@0+(1,0)[0|1] "" Vector__XXX
 SG_ TBOXRemainNetworkWakeUpReason15 : 46|1@0+(1,0)[0|1] "" Vector__XXX
 SG_ TBOXRemainNetworkWakeUpReason16 : 47|1@0+(1,0)[0|1] "" Vector__XXX
 SG_ TBOXRemainNetworkWakeUpReason17 : 48|1@0+(1,0)[0|1] "" Vector__XXX
 SG_ TBOXRemainNetworkWakeUpReason18 : 49|1@0+(1,0)[0|1] "" Vector__XXX
 SG_ TBOXRemainNetworkWakeUpReason19 : 50|1@0+(1,0)[0|1] "" Vector__XXX
 SG_ TBOXRemainNetworkWakeUpReason20 : 51|1@0+(1,0)[0|1] "" Vector__XXX
 SG_ TBOXRemainNetworkWakeUpReason21 : 52|1@0+(1,0)[0|1] "" Vector__XXX
 SG_ TBOXRemainNetworkWakeUpReason22 : 53|1@0+(1,0)[0|1] "" Vector__XXX
 SG_ TBOXRemainNetworkWakeUpReason23 : 54|1@0+(1,0)[0|1] "" Vector__XXX
 SG_ TBOXRemainNetworkWakeUpReason24 : 55|1@0+(1,0)[0|1] "" Vector__XXX
 SG_ TBOXUserData5 : 63|8@0+(1,0)[0|255] "" Vector__XXX
BO_ 517 ESC_Fr03_205: 8 ESC
 SG_ AVHLampReq_@2WR1025 : 34|2@0+(1,0)[0|3] "" Vector__XXX
BO_ 531 EGSM_Fr01_213: 8 EGSM
 SG_ EGSMErrorSts_@2WR1026 : 7|1@0+(1,0)[0|1] "" Vector__XXX
 SG_ EXTEGSMErrorSts_@2WG705B : 7|1@0+(1,0)[0|1] "" Vector__XXX

BA_DEF_  "HSBaudrate" ENUM  "50000","100000","125000","250000","500000","1000000";
BA_DEF_  "MSBaudrate" ENUM  "50000","100000","125000","250000","500000","1000000";
BA_DEF_ BO_  "VFrameFormat" ENUM  "StandardCAN","ExtendedCAN","reserved","J1939PG";

BA_ "HSBaudrate" 4;
BA_ "MSBaudrate" 4;
BA_ "VFrameFormat" BO_ 563 0;
BA_ "VFrameFormat" BO_ 825 0;
BA_ "VFrameFormat" BO_ 601 0;
BA_ "VFrameFormat" BO_ 618 0;
BA_ "VFrameFormat" BO_ 906 0;
BA_ "VFrameFormat" BO_ 874 0;
BA_ "VFrameFormat" BO_ 225 0;
BA_ "VFrameFormat" BO_ 481 0;
BA_ "VFrameFormat" BO_ 872 0;
BA_ "VFrameFormat" BO_ 914 0;
BA_ "VFrameFormat" BO_ 858 0;
BA_ "VFrameFormat" BO_ 904 0;
BA_ "VFrameFormat" BO_ 646 0;
BA_ "VFrameFormat" BO_ 631 0;
BA_ "VFrameFormat" BO_ 1288 0;
BA_ "VFrameFormat" BO_ 1001 0;
BA_ "VFrameFormat" BO_ 666 0;
BA_ "VFrameFormat" BO_ 1291 0;
BA_ "VFrameFormat" BO_ 170 0;
BA_ "VFrameFormat" BO_ 187 0;
BA_ "VFrameFormat" BO_ 972 0;
BA_ "VFrameFormat" BO_ 1072 0;
BA_ "VFrameFormat" BO_ 200 0;
BA_ "VFrameFormat" BO_ 850 0;
BA_ "VFrameFormat" BO_ 1251 0;
BA_ "VFrameFormat" BO_ 1236 0;
BA_ "VFrameFormat" BO_ 426 0;
BA_ "VFrameFormat" BO_ 487 0;
BA_ "VFrameFormat" BO_ 1433 0;
BA_ "VFrameFormat" BO_ 1034 0;
BA_ "VFrameFormat" BO_ 1030 0;
BA_ "VFrameFormat" BO_ 778 0;
BA_ "VFrameFormat" BO_ 547 0;
BA_ "VFrameFormat" BO_ 1067 0;
BA_ "VFrameFormat" BO_ 1301 0;
BA_ "VFrameFormat" BO_ 1328 0;
BA_ "VFrameFormat" BO_ 1088 0;
BA_ "VFrameFormat" BO_ 1093 0;
BA_ "VFrameFormat" BO_ 454 0;
BA_ "VFrameFormat" BO_ 456 0;
BA_ "VFrameFormat" BO_ 229 0;
BA_ "VFrameFormat" BO_ 622 0;
BA_ "VFrameFormat" BO_ 654 0;
BA_ "VFrameFormat" BO_ 657 0;
BA_ "VFrameFormat" BO_ 638 0;
BA_ "VFrameFormat" BO_ 661 0;
BA_ "VFrameFormat" BO_ 1304 0;
BA_ "VFrameFormat" BO_ 1345 0;
BA_ "VFrameFormat" BO_ 1374 0;
BA_ "VFrameFormat" BO_ 1952 0;
BA_ "VFrameFormat" BO_ 1968 0;
BA_ "VFrameFormat" BO_ 2015 0;
BA_ "VFrameFormat" BO_ 1013 0;
BA_ "VFrameFormat" BO_ 1032 0;
BA_ "VFrameFormat" BO_ 853 0;
BA_ "VFrameFormat" BO_ 885 0;
BA_ "VFrameFormat" BO_ 917 0;
BA_ "VFrameFormat" BO_ 926 0;
BA_ "VFrameFormat" BO_ 920 0;
BA_ "VFrameFormat" BO_ 542 0;
BA_ "VFrameFormat" BO_ 1317 0;
BA_ "VFrameFormat" BO_ 1318 0;
BA_ "VFrameFormat" BO_ 1319 0;
BA_ "VFrameFormat" BO_ 1321 0;
BA_ "VFrameFormat" BO_ 1311 0;
BA_ "VFrameFormat" BO_ 1298 0;
BA_ "VFrameFormat" BO_ 1326 0;
BA_ "VFrameFormat" BO_ 951 0;
BA_ "VFrameFormat" BO_ 912 0;
BA_ "VFrameFormat" BO_ 1430 0;
BA_ "VFrameFormat" BO_ 1431 0;
BA_ "VFrameFormat" BO_ 1432 0;
BA_ "VFrameFormat" BO_ 1537 0;

BA_ "IN_VEHITYPE" 01;
BA_ "IN_VEHISTATE_00" 02
BA_ "IN_VEHISTATE_01" 01
BA_ "IN_VEHISTATE_02" 01
BA_ "IN_VEHISTATE_03" 01

BA_ "IN_CHGSTATE_00"  03
BA_ "IN_CHGSTATE_05"  03
BA_ "IN_CHGSTATE_01"  01
BA_ "IN_CHGSTATE_02"  01
BA_ "IN_CHGSTATE_06"  01
BA_ "IN_CHGSTATE_03"  04
BA_ "IN_CHGSTATE_04"  FE

BA_ "IN_DCDCSTATE_00" 02
BA_ "IN_DCDCSTATE_01" 01
BA_ "IN_DCDCSTATE_02" FE

BA_ "IN_SHIFT_05" N
BA_ "IN_SHIFT_06" N
BA_ "IN_SHIFT_08" S
BA_ "IN_SHIFT_0A" P
BA_ "IN_SHIFT_0B" D
BA_ "IN_SHIFT_0C" N
BA_ "IN_SHIFT_0D" R
BA_ "IN_SHIFT_0E" P
BA_ "IN_SHIFT_0F" FF

BA_ "IN_MOTSTATE0_03" 01
BA_ "IN_MOTSTATE0_04" 01
BA_ "IN_MOTSTATE0_05" 01
BA_ "IN_MOTSTATE0_07" 01
BA_ "IN_MOTSTATE0_02" 02
BA_ "IN_MOTSTATE0_00" 03
BA_ "IN_MOTSTATE0_06" 04
BA_ "IN_MOTSTATE0_01" FE

BA_ "SigDefault" BMS1StateOfCharge 255
BA_ "SigDefault" BMS8SumOfCellNum  1
BA_ "SigDefault" BMS8SumOfTSnsrNum 1
BA_ "SigDefault" BMS11BattTempSensorNum 0
BA_ "SigDefault" BMS11BattCellNum1 0
BA_ "SigDefault" BMS11BattCellNum2 0
BA_ "SigDefault" CLMLHTemp 16
BA_ "SigDefault" CLMRHTemp 16
BA_ "SigDefault" CLMOutletTemp 20
BA_ "SigDefault" CLMInsideTemp 25
BA_ "SigDefault" CLMOutsideTemp 25
BA_ "SigDefault" VCU2_HVIL_MajorLoop 1
BA_ "SigDefault" MCU3_HVIL_DCBus 1
